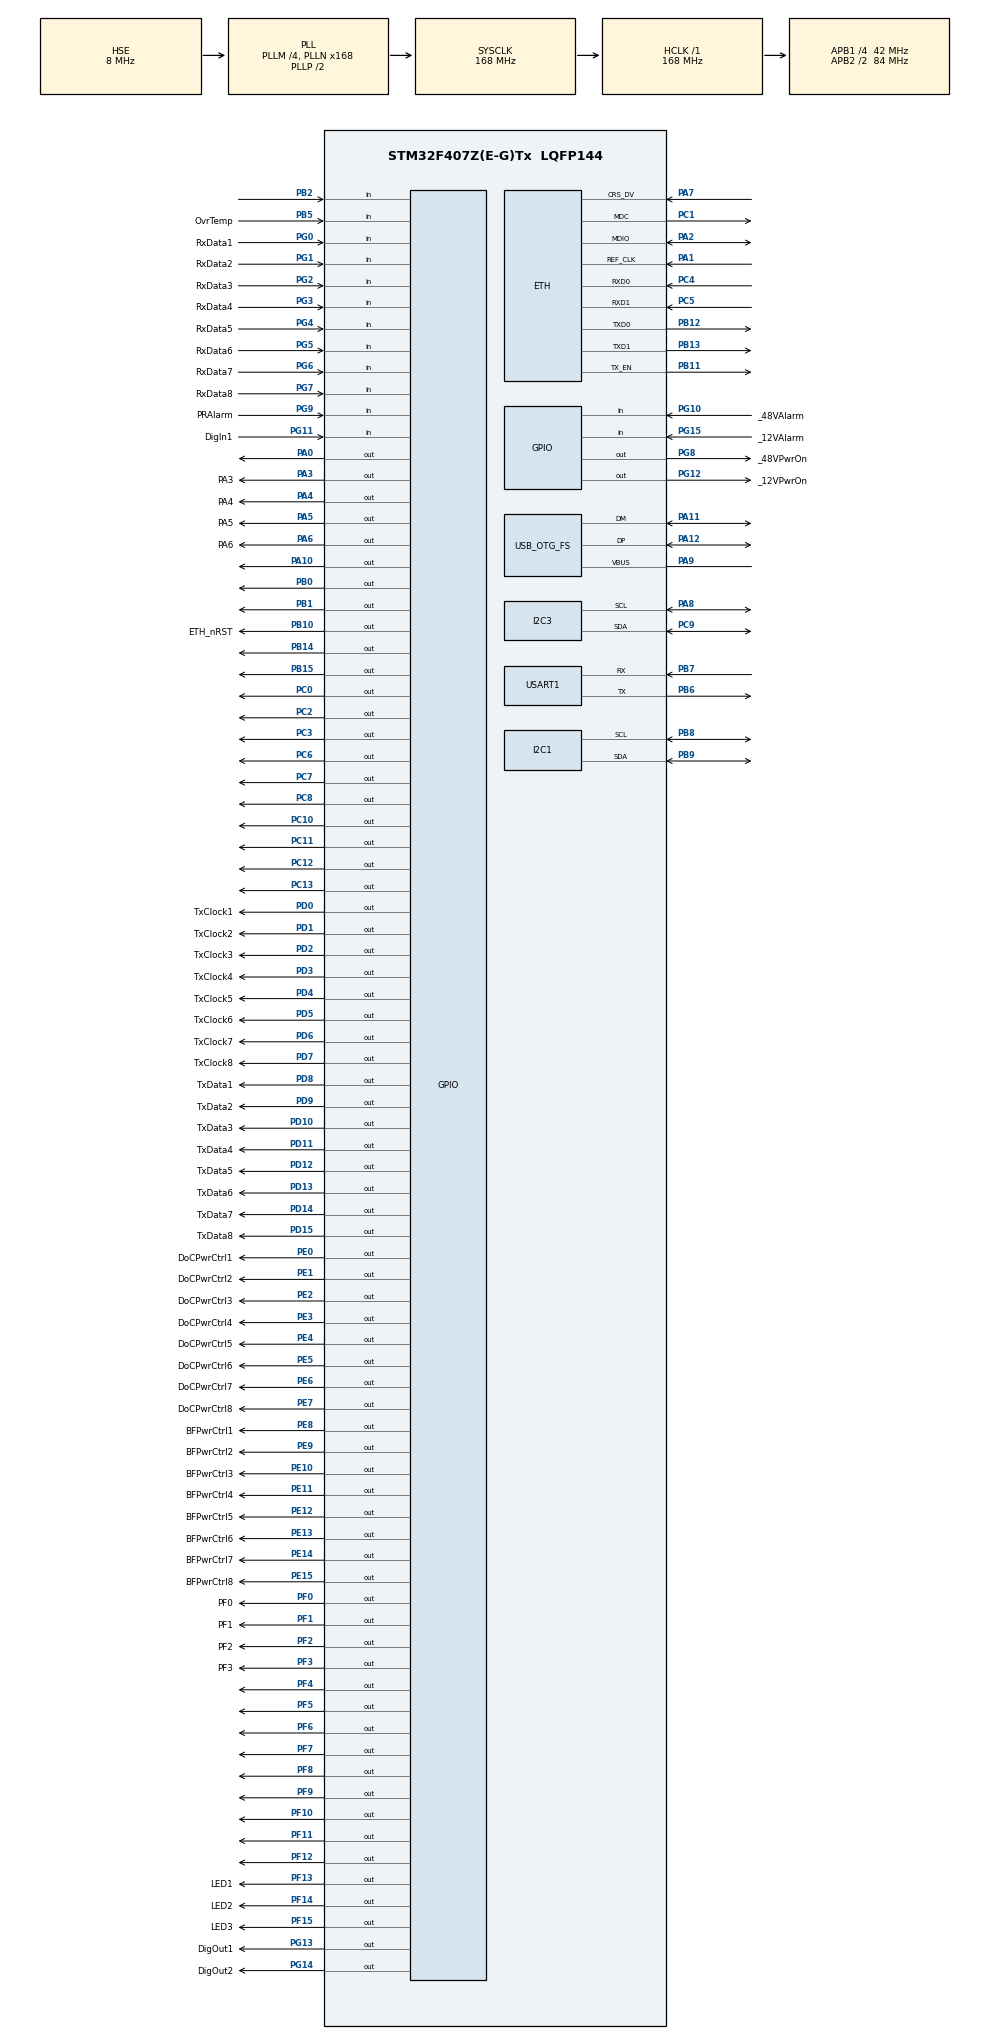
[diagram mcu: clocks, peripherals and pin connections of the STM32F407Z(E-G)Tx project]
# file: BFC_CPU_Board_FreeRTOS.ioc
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ETH.MediaInterface=HAL_ETH_RMII_MODE
ETH.PHY_DUPLEX_STATUS=0x0010
ETH.PHY_ISFR_INT4=0x0010
ETH.PHY_SPEED_STATUS=0x0004
ETH.PHY_SR=0x1F
ETH.RxMode=ETH_RXINTERRUPT_MODE
FREERTOS.Tasks01=defaultTask,24,768,StartDefaultTask,Default,NULL,Dynamic,NULL,NULL;ManageMQTTConn,40,768,StartMQTTConn,Default,NULL,Dynamic,NULL,NULL;PingWatchdog,8,768,StartPingWD,Default,NULL,Dynamic,NULL,NULL;Telemetry,24,768,StartTelemetry,Default,NULL,Dynamic,NULL,NULL
FREERTOS.configCHECK_FOR_STACK_OVERFLOW=2
FREERTOS.configENABLE_FPU=1
FREERTOS.configLIBRARY_LOWEST_INTERRUPT_PRIORITY=14
FREERTOS.configMINIMAL_STACK_SIZE=768
FREERTOS.configTOTAL_HEAP_SIZE=32768
FREERTOS.configUSE_NEWLIB_REENTRANT=1
I2C1.I2C_Mode=I2C_Fast
I2C3.I2C_Mode=I2C_Fast
Mcu.Family=STM32F4
Mcu.Name=STM32F407Z(E-G)Tx
Mcu.Package=LQFP144
NVIC.ETH_IRQn=true\:5\:0\:false\:false\:true\:true\:false\:true\:true
NVIC.I2C1_EV_IRQn=true\:12\:0\:true\:false\:true\:true\:true\:true\:true
NVIC.I2C3_EV_IRQn=true\:13\:0\:true\:false\:true\:true\:true\:true\:true
NVIC.OTG_FS_IRQn=true\:10\:0\:true\:false\:true\:true\:false\:true\:true
NVIC.PriorityGroup=NVIC_PRIORITYGROUP_4
NVIC.TIM2_IRQn=true\:11\:0\:true\:false\:true\:true\:true\:true\:true
NVIC.TIM7_IRQn=true\:14\:0\:true\:false\:true\:false\:false\:true\:true
NVIC.TimeBase=TIM7_IRQn
NVIC.TimeBaseIP=TIM7
NVIC.USART1_IRQn=true\:14\:0\:true\:false\:true\:true\:true\:true\:true
PA0-WKUP.Signal=GPIO_Output
PA1.Mode=RMII
PA1.Signal=ETH_REF_CLK
PA10.Signal=GPIO_Output
PA11.Mode=Device_Only
PA11.Signal=USB_OTG_FS_DM
PA12.Mode=Device_Only
PA12.Signal=USB_OTG_FS_DP
PA13.Mode=JTAG_5_pins
PA13.Signal=SYS_JTMS-SWDIO
PA14.Mode=JTAG_5_pins
PA14.Signal=SYS_JTCK-SWCLK
PA15.Mode=JTAG_5_pins
PA15.Signal=SYS_JTDI
PA2.Mode=RMII
PA2.Signal=ETH_MDIO
PA3.GPIO_Label=PA3
PA3.Signal=GPIO_Output
PA4.GPIO_Label=PA4
PA4.Signal=GPIO_Output
PA5.GPIO_Label=PA5
PA5.Signal=GPIO_Output
PA6.GPIO_Label=PA6
PA6.Signal=GPIO_Output
PA7.Mode=RMII
PA7.Signal=ETH_CRS_DV
PA8.Mode=I2C
PA8.Signal=I2C3_SCL
PA9.Mode=Activate_VBUS
PA9.Signal=USB_OTG_FS_VBUS
PB0.Signal=GPIO_Output
PB1.Signal=GPIO_Output
PB10.GPIO_Label=ETH_nRST
PB10.GPIO_Speed=GPIO_SPEED_FREQ_LOW
PB10.PinState=GPIO_PIN_SET
PB10.Signal=GPIO_Output
PB11.Mode=RMII
PB11.Signal=ETH_TX_EN
PB12.Mode=RMII
PB12.Signal=ETH_TXD0
PB13.Mode=RMII
PB13.Signal=ETH_TXD1
PB14.Signal=GPIO_Output
PB15.Signal=GPIO_Output
PB2.Signal=GPIO_Input
PB3.Mode=JTAG_5_pins
PB3.Signal=SYS_JTDO-SWO
PB4.Mode=JTAG_5_pins
PB4.Signal=SYS_JTRST
PB5.GPIO_Label=OvrTemp
PB5.Signal=GPIO_Input
PB6.Mode=Asynchronous
PB6.Signal=USART1_TX
PB7.Mode=Asynchronous
PB7.Signal=USART1_RX
PB8.Mode=I2C
PB8.Signal=I2C1_SCL
PB9.Mode=I2C
PB9.Signal=I2C1_SDA
PC0.Signal=GPIO_Output
PC1.Mode=RMII
PC1.Signal=ETH_MDC
PC10.Signal=GPIO_Output
PC11.Signal=GPIO_Output
PC12.Signal=GPIO_Output
PC13-ANTI_TAMP.Signal=GPIO_Output
PC14-OSC32_IN.Mode=LSE-External-Oscillator
PC14-OSC32_IN.Signal=RCC_OSC32_IN
PC15-OSC32_OUT.Mode=LSE-External-Oscillator
PC15-OSC32_OUT.Signal=RCC_OSC32_OUT
PC2.Signal=GPIO_Output
PC3.Signal=GPIO_Output
PC4.Mode=RMII
PC4.Signal=ETH_RXD0
PC5.Mode=RMII
PC5.Signal=ETH_RXD1
PC6.Signal=GPIO_Output
PC7.Signal=GPIO_Output
PC8.Signal=GPIO_Output
PC9.Mode=I2C
PC9.Signal=I2C3_SDA
PD0.GPIO_Label=TxClock1
PD0.GPIO_ModeDefaultOutputPP=GPIO_MODE_OUTPUT_PP
PD0.GPIO_Speed=GPIO_SPEED_FREQ_HIGH
PD0.Signal=GPIO_Output
PD1.GPIO_Label=TxClock2
PD1.GPIO_ModeDefaultOutputPP=GPIO_MODE_OUTPUT_PP
PD1.GPIO_Speed=GPIO_SPEED_FREQ_HIGH
PD1.Signal=GPIO_Output
PD10.GPIO_Label=TxData3
PD10.GPIO_ModeDefaultOutputPP=GPIO_MODE_OUTPUT_PP
PD10.GPIO_Speed=GPIO_SPEED_FREQ_HIGH
PD10.Signal=GPIO_Output
PD11.GPIO_Label=TxData4
PD11.GPIO_ModeDefaultOutputPP=GPIO_MODE_OUTPUT_PP
PD11.GPIO_Speed=GPIO_SPEED_FREQ_HIGH
PD11.Signal=GPIO_Output
PD12.GPIO_Label=TxData5
PD12.GPIO_ModeDefaultOutputPP=GPIO_MODE_OUTPUT_PP
PD12.GPIO_Speed=GPIO_SPEED_FREQ_HIGH
PD12.Signal=GPIO_Output
PD13.GPIO_Label=TxData6
PD13.GPIO_ModeDefaultOutputPP=GPIO_MODE_OUTPUT_PP
PD13.GPIO_Speed=GPIO_SPEED_FREQ_HIGH
PD13.Signal=GPIO_Output
PD14.GPIO_Label=TxData7
PD14.GPIO_ModeDefaultOutputPP=GPIO_MODE_OUTPUT_PP
PD14.GPIO_Speed=GPIO_SPEED_FREQ_HIGH
PD14.Signal=GPIO_Output
PD15.GPIO_Label=TxData8
PD15.GPIO_ModeDefaultOutputPP=GPIO_MODE_OUTPUT_PP
PD15.GPIO_Speed=GPIO_SPEED_FREQ_HIGH
PD15.Signal=GPIO_Output
PD2.GPIO_Label=TxClock3
PD2.GPIO_ModeDefaultOutputPP=GPIO_MODE_OUTPUT_PP
PD2.GPIO_Speed=GPIO_SPEED_FREQ_HIGH
PD2.Signal=GPIO_Output
PD3.GPIO_Label=TxClock4
PD3.GPIO_ModeDefaultOutputPP=GPIO_MODE_OUTPUT_PP
PD3.GPIO_Speed=GPIO_SPEED_FREQ_HIGH
PD3.Signal=GPIO_Output
PD4.GPIO_Label=TxClock5
PD4.GPIO_ModeDefaultOutputPP=GPIO_MODE_OUTPUT_PP
PD4.GPIO_Speed=GPIO_SPEED_FREQ_HIGH
PD4.Signal=GPIO_Output
PD5.GPIO_Label=TxClock6
PD5.GPIO_ModeDefaultOutputPP=GPIO_MODE_OUTPUT_PP
PD5.GPIO_Speed=GPIO_SPEED_FREQ_HIGH
PD5.Signal=GPIO_Output
PD6.GPIO_Label=TxClock7
PD6.GPIO_ModeDefaultOutputPP=GPIO_MODE_OUTPUT_PP
PD6.GPIO_Speed=GPIO_SPEED_FREQ_HIGH
PD6.Signal=GPIO_Output
PD7.GPIO_Label=TxClock8
PD7.GPIO_ModeDefaultOutputPP=GPIO_MODE_OUTPUT_PP
PD7.GPIO_Speed=GPIO_SPEED_FREQ_HIGH
PD7.Signal=GPIO_Output
PD8.GPIO_Label=TxData1
PD8.GPIO_ModeDefaultOutputPP=GPIO_MODE_OUTPUT_PP
PD8.GPIO_Speed=GPIO_SPEED_FREQ_HIGH
PD8.Signal=GPIO_Output
PD9.GPIO_Label=TxData2
PD9.GPIO_ModeDefaultOutputPP=GPIO_MODE_OUTPUT_PP
PD9.GPIO_Speed=GPIO_SPEED_FREQ_HIGH
PD9.Signal=GPIO_Output
PE0.GPIO_Label=DoCPwrCtrl1
PE0.Signal=GPIO_Output
PE1.GPIO_Label=DoCPwrCtrl2
PE1.Signal=GPIO_Output
PE10.GPIO_Label=BFPwrCtrl3
PE10.Signal=GPIO_Output
PE11.GPIO_Label=BFPwrCtrl4
PE11.Signal=GPIO_Output
PE12.GPIO_Label=BFPwrCtrl5
PE12.Signal=GPIO_Output
PE13.GPIO_Label=BFPwrCtrl6
PE13.Signal=GPIO_Output
PE14.GPIO_Label=BFPwrCtrl7
PE14.Signal=GPIO_Output
PE15.GPIO_Label=BFPwrCtrl8
PE15.Signal=GPIO_Output
PE2.GPIO_Label=DoCPwrCtrl3
PE2.Signal=GPIO_Output
PE3.GPIO_Label=DoCPwrCtrl4
PE3.Signal=GPIO_Output
PE4.GPIO_Label=DoCPwrCtrl5
PE4.Signal=GPIO_Output
PE5.GPIO_Label=DoCPwrCtrl6
PE5.Signal=GPIO_Output
PE6.GPIO_Label=DoCPwrCtrl7
PE6.Signal=GPIO_Output
PE7.GPIO_Label=DoCPwrCtrl8
PE7.Signal=GPIO_Output
PE8.GPIO_Label=BFPwrCtrl1
PE8.Signal=GPIO_Output
PE9.GPIO_Label=BFPwrCtrl2
PE9.Signal=GPIO_Output
PF0.GPIO_Label=PF0
PF0.Signal=GPIO_Output
PF1.GPIO_Label=PF1
PF1.Signal=GPIO_Output
PF10.Signal=GPIO_Output
PF11.Signal=GPIO_Output
PF12.Signal=GPIO_Output
PF13.GPIO_Label=LED1
PF13.Signal=GPIO_Output
PF14.GPIO_Label=LED2
PF14.Signal=GPIO_Output
PF15.GPIO_Label=LED3
PF15.Signal=GPIO_Output
PF2.GPIO_Label=PF2
PF2.Signal=GPIO_Output
PF3.GPIO_Label=PF3
PF3.Signal=GPIO_Output
PF4.Signal=GPIO_Output
PF5.Signal=GPIO_Output
PF6.Signal=GPIO_Output
PF7.Signal=GPIO_Output
PF8.Signal=GPIO_Output
PF9.Signal=GPIO_Output
PG0.GPIO_Label=RxData1
PG0.Signal=GPIO_Input
PG1.GPIO_Label=RxData2
PG1.Signal=GPIO_Input
PG10.GPIO_Label=_48VAlarm
PG10.Signal=GPIO_Input
PG11.GPIO_Label=DigIn1
PG11.Signal=GPIO_Input
PG12.GPIO_Label=_12VPwrOn
PG12.Signal=GPIO_Output
PG13.GPIO_Label=DigOut1
PG13.Signal=GPIO_Output
PG14.GPIO_Label=DigOut2
PG14.Signal=GPIO_Output
PG15.GPIO_Label=_12VAlarm
PG15.Signal=GPIO_Input
PG2.GPIO_Label=RxData3
PG2.Signal=GPIO_Input
PG3.GPIO_Label=RxData4
PG3.Signal=GPIO_Input
PG4.GPIO_Label=RxData5
PG4.Signal=GPIO_Input
PG5.GPIO_Label=RxData6
PG5.Signal=GPIO_Input
PG6.GPIO_Label=RxData7
PG6.Signal=GPIO_Input
PG7.GPIO_Label=RxData8
PG7.Signal=GPIO_Input
PG8.GPIO_Label=_48VPwrOn
PG8.Signal=GPIO_Output
PG9.GPIO_Label=PRAlarm
PG9.Signal=GPIO_Input
PH0-OSC_IN.Mode=HSE-External-Oscillator
PH0-OSC_IN.Signal=RCC_OSC_IN
PH1-OSC_OUT.Mode=HSE-External-Oscillator
PH1-OSC_OUT.Signal=RCC_OSC_OUT
ProjectManager.HeapSize=0x200
ProjectManager.StackSize=0x400
ProjectManager.TargetToolchain=STM32CubeIDE
RCC.48MHZClocksFreq_Value=48000000
RCC.AHBFreq_Value=168000000
RCC.APB1CLKDivider=RCC_HCLK_DIV4
RCC.APB1Freq_Value=42000000
RCC.APB1TimFreq_Value=84000000
RCC.APB2CLKDivider=RCC_HCLK_DIV2
RCC.APB2Freq_Value=84000000
RCC.APB2TimFreq_Value=168000000
RCC.CortexFreq_Value=168000000
RCC.HCLKFreq_Value=168000000
RCC.HSE_VALUE=8000000
RCC.HSI_VALUE=16000000
RCC.PLLM=4
RCC.PLLN=168
RCC.PLLQ=7
RCC.RCC_RTC_Clock_Source=RCC_RTCCLKSOURCE_LSE
RCC.RCC_RTC_Clock_SourceVirtual=RCC_RTCCLKSOURCE_LSE
RCC.SYSCLKFreq_VALUE=168000000
RCC.SYSCLKSource=RCC_SYSCLKSOURCE_PLLCLK
RCC.VCOOutputFreq_Value=336000000
RTC.Format=RTC_FORMAT_BCD
RTC.Year=22
TIM2.AutoReloadPreload=TIM_AUTORELOAD_PRELOAD_ENABLE
TIM2.CounterMode=TIM_COUNTERMODE_DOWN
TIM2.Period=83999999
TIM6.AutoReloadPreload=TIM_AUTORELOAD_PRELOAD_ENABLE
TIM6.Prescaler=83
USART1.VirtualMode=VM_ASYNC
USB_DEVICE.CLASS_NAME_FS=DFU
USB_DEVICE.VirtualMode-DFU_FS=Dfu
USB_DEVICE.VirtualModeFS=Dfu_FS
USB_OTG_FS.VirtualMode=Device_Only
VP_CRC_VS_CRC.Mode=CRC_Activate
VP_FREERTOS_VS_CMSIS_V2.Mode=CMSIS_V2
VP_RNG_VS_RNG.Mode=RNG_Activate
VP_RTC_VS_RTC_Activate.Mode=RTC_Enabled
VP_RTC_VS_RTC_Calendar.Mode=RTC_Calendar
VP_SYS_VS_tim7.Mode=TIM7
VP_TIM2_VS_ClockSourceINT.Mode=Internal
VP_TIM6_VS_ClockSourceINT.Mode=Enable_Timer
VP_USB_DEVICE_VS_USB_DEVICE_DFU_FS.Mode=DFU_FS
board=custom

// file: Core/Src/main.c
/* USER CODE BEGIN Header */
/**
  ******************************************************************************
  * @file           : main.c
  * @brief          : Main program body
  ******************************************************************************
  * @attention
  *
  * Copyright (c) 2023 STMicroelectronics.
  * All rights reserved.
  *
  * This software is licensed under terms that can be found in the LICENSE file
  * in the root directory of this software component.
  * If no LICENSE file comes with this software, it is provided AS-IS.
  *
  ******************************************************************************
  */
/* USER CODE END Header */
#include "main.h"
#include "cmsis_os.h"
#include "crc.h"
#include "eth.h"
#include "i2c.h"
#include "iwdg.h"
#include "rng.h"
#include "rtc.h"
#include "tim.h"
#include "usart.h"
#include "usb_device.h"
#include "gpio.h"

/* USER CODE BEGIN Includes */
#include "FreeRTOS.h"
#include "cJSON.h"
//#include <stdio.h>
#include "bfc_config.h"
/* USER CODE END Includes */

/* USER CODE BEGIN PV */

//uint8_t ucHeap[ configTOTAL_HEAP_SIZE ] __attribute__ ((section (".ccmram")));

struct bf_struct beamformer[8] __attribute__ ((section (".ccmram")));
struct bfc_struct bfController __attribute__ ((section (".ccmram")));
unsigned long unixTime = 0;
unsigned long nextPointTime = LONG_TIME_AWAY;

/* USER CODE END PV */

void SystemClock_Config(void);
void MX_FREERTOS_Init(void);
/* USER CODE BEGIN PFP */
void intTo6bits(int value, char *buffer);
void intToXbits(int value, char *buffer, int bits);
void gen_bitstring(int xdelays[], int ydelays[], char *outlist);
void send_bitstring_en(uint8_t bfEnable, float *bf_temp, uint8_t *bf_flags);
void sntp_SetSystemTime(uint32_t sec, uint32_t us);
void parsePointing(const uint8_t *data, int len);
void parseBFPower(const uint8_t *data, int len);
void parseDoCPower(const uint8_t *data, int len);
void doBFTest();
void sendBFPointing();

extern void sendPointingResult();
extern void sendLog(const char *logLevel, const char *logMsg);
/* USER CODE END PFP */

/* USER CODE BEGIN 0 */

void ActivateEthPhy(void) // Release LAN8742 reset pin
{
	HAL_GPIO_WritePin(ETH_nRST_GPIO_Port, ETH_nRST_Pin, GPIO_PIN_SET);
}

void DeactivateEthPhy(void) // Hold LAN8742 in reset
{
	HAL_GPIO_WritePin(ETH_nRST_GPIO_Port, ETH_nRST_Pin, GPIO_PIN_RESET);
}

void delay_us(unsigned int us)
{
	__HAL_TIM_SET_COUNTER(&htim6,0);  // set the counter value a 0
	while (__HAL_TIM_GET_COUNTER(&htim6) < us);  // wait for the counter to reach the us input in the parameter
}

#ifdef __GNUC__
#define PUTCHAR_PROTOTYPE int __io_putchar(int ch)
#else
#define PUTCHAR_PROTOTYPE int fputc(int ch, FILE *f)
#endif
PUTCHAR_PROTOTYPE
{
	// Uncomment one line to select where printf() commands send their characters
	// HAL_UART for UART1 pins, or ITM_SendChar for the SWV debugger
	//HAL_UART_Transmit(&huart1, (uint8_t *)&ch, 1, HAL_MAX_DELAY);
	ITM_SendChar(ch);
	return ch;
}

/* USER CODE END 0 */

int main(void)
{

  /* MCU Configuration--------------------------------------------------------*/

  /* Reset of all peripherals, Initializes the Flash interface and the Systick. */
  HAL_Init();

  /* Configure the system clock */
  SystemClock_Config();

  /* Initialize all configured peripherals */
  MX_GPIO_Init();
  MX_I2C1_Init();
  MX_I2C3_Init();
  MX_USART1_UART_Init();
  MX_RTC_Init();
  MX_CRC_Init();
  MX_RNG_Init();
  MX_TIM6_Init();
  MX_TIM2_Init();
  MX_ETH_Init();
  MX_IWDG_Init();
  /* USER CODE BEGIN 2 */
  HAL_TIM_Base_Start(&htim6); // Start the 1 us timer
  HAL_TIM_Base_Start_IT(&htim2); // Start the 1 s overflow unixTime timer, enable interrupt

  ActivateEthPhy();
  GPIOD->BSRR = 0xFFFF0000; // Set Port D all bits/clocks low
  HAL_Delay(200);

  /* USER CODE END 2 */

  /* Init scheduler */
  osKernelInitialize();  /* Call init function for freertos objects (in freertos.c) */
  MX_FREERTOS_Init();

  // Pat the watchdog
  HAL_IWDG_Refresh(&hiwdg);

  /* Start scheduler */
  osKernelStart();

  /* We should never get here as control is now taken by the scheduler */
  /* Infinite loop */
  while (1)
  {

  }
}

void SystemClock_Config(void)
{
  RCC_OscInitTypeDef RCC_OscInitStruct = {0};
  RCC_ClkInitTypeDef RCC_ClkInitStruct = {0};

  /** Configure the main internal regulator output voltage
  */
  __HAL_RCC_PWR_CLK_ENABLE();
  __HAL_PWR_VOLTAGESCALING_CONFIG(PWR_REGULATOR_VOLTAGE_SCALE1);

  /** Initializes the RCC Oscillators according to the specified parameters
  * in the RCC_OscInitTypeDef structure.
  */
  RCC_OscInitStruct.OscillatorType = RCC_OSCILLATORTYPE_LSI | RCC_OSCILLATORTYPE_HSE | RCC_OSCILLATORTYPE_LSE;
  RCC_OscInitStruct.HSEState = RCC_HSE_ON;
  RCC_OscInitStruct.LSEState = RCC_LSE_ON;
  RCC_OscInitStruct.LSIState = RCC_LSI_ON;
  RCC_OscInitStruct.PLL.PLLState = RCC_PLL_ON;
  RCC_OscInitStruct.PLL.PLLSource = RCC_PLLSOURCE_HSE;
  RCC_OscInitStruct.PLL.PLLM = 4;
  RCC_OscInitStruct.PLL.PLLN = 168;
  RCC_OscInitStruct.PLL.PLLP = RCC_PLLP_DIV2;
  RCC_OscInitStruct.PLL.PLLQ = 7;
  if (HAL_RCC_OscConfig(&RCC_OscInitStruct) != HAL_OK)
  {
    Error_Handler();
  }

  /** Initializes the CPU, AHB and APB buses clocks
  */
  RCC_ClkInitStruct.ClockType = RCC_CLOCKTYPE_HCLK|RCC_CLOCKTYPE_SYSCLK
                              |RCC_CLOCKTYPE_PCLK1|RCC_CLOCKTYPE_PCLK2;
  RCC_ClkInitStruct.SYSCLKSource = RCC_SYSCLKSOURCE_PLLCLK;
  RCC_ClkInitStruct.AHBCLKDivider = RCC_SYSCLK_DIV1;
  RCC_ClkInitStruct.APB1CLKDivider = RCC_HCLK_DIV4;
  RCC_ClkInitStruct.APB2CLKDivider = RCC_HCLK_DIV2;

  if (HAL_RCC_ClockConfig(&RCC_ClkInitStruct, FLASH_LATENCY_5) != HAL_OK)
  {
    Error_Handler();
  }
}

/* USER CODE BEGIN 4 */
void gen_bitstring(int xdelays[], int ydelays[], char *outstring)
/* Given two arrays of 16x 16-bit integers representing the X and Y delays, return a string containing 253
 * characters each '1' or '0' representing the bitstream to send to the beamformer.
 */
{
	int i=0, x=0, y=0, chksum=0;
	char buffer[sizeof(int)*8+1] = "";
	char xdelays_b[16*6+1] = "", ydelays_b[16*6+1] = ""; // Packed 16 x 6-bit (96 bits) binary delays as strings
	int chk_words[12];

	strcpy(outstring, "00000000111100000000000000000000"); // Preamble 32 bits
	i = 32; // Start adding bits after preamble at pos 32

	// Convert 16x xdelay integers into 6-bit binary values packed in a 96 bit string
	for (x=0; x<=15; x++) { // For each integer in the xdelays array
		intToXbits(xdelays[x], buffer, 6);
		strcat(xdelays_b, buffer);
	}
	// Convert 16x ydelay integers into 6-bit binary values packed in a 96 bit string
	for (y=0; y<=15; y++) { // For each integer in the ydelays array
		intToXbits(ydelays[y], buffer, 6);
		strcat(ydelays_b, buffer);
	}

	// Extract first 6x 16-bit integers from x delay packed string and add to output
	for (x=0; x<=5; x++) { // For each word in the first group of 6
		for (y=0; y<=16; y++) { // For each bit in the 16-bit word
			if (y != 16) {
				outstring[i] = xdelays_b[x*16+y];
				buffer[y] = xdelays_b[x*16+y];
			}
			else {
				outstring[i] = '1'; // Add 1's for spacing between words on output
			}
			i++;
		}
		buffer[16] = '\0';
		chk_words[x] = (int) strtol(buffer, NULL ,2);
	}
	// Extract the second 6x 16-bit integers from y delay packed string and add to output
	for (x=6; x<=11; x++) { // For each word in the second group of 6
		for (y=0; y<=16; y++) { // For each bit in the 16-bit word
			if (y != 16) {
				outstring[i] = ydelays_b[(x-6)*16+y];
				buffer[y] = ydelays_b[(x-6)*16+y];
			}
			else {
				outstring[i] = '1'; // Add 1's for spacing between words on output
			}
			i++;
		}
		buffer[16] = '\0';
		chk_words[x] = (int) strtol(buffer, NULL ,2);
	}

	// Calculate checksum: the 12x 16-bit packed delay words XORed together
	for (x=0; x<=11; x++) { // For each 16-bit word in the packed bit strings array
		chksum = chksum ^ chk_words[x]; // Bitwise XOR
	}

	// Add 16-bit checksum to output string
	intToXbits(chksum, buffer, 16);
	for (x=0; x<=15; x++) { // For each bit in the checksum buffer
		if(buffer[x] == '0' || buffer[x] == '1') outstring[i] = buffer[x];
		else outstring[i] = '0';
		i++;
	}

	// Add one more 1 for good measure
	outstring[i] = '1';
	i++;

	// Add termination null
	outstring[i] = '\0';

	//printf("Outstring %d bits: %s\n", strlen(outstring), outstring);
}

void intToXbits(int value, char *buffer, int bits) {
/*
 * Converts the least-significant <bits> bits from <value> into a string of
 * '1' and '0' chars in <*buffer> terminated with a \0. Caution: Does no
 * checking of realistic values or if <*buffer> is large enough to hold the result.
 */
	int i = 0;
	for (int mask = 0x01 << (bits - 1); mask > 0; mask >>= 1) {
		buffer[i++] = (value & mask) ? '1':'0';
	}
	buffer[i++] = '\0';
}

void send_bitstring_en(uint8_t bfEnable, float *bf_temp, uint8_t *bf_flags)
/*
 * outstring is a 253 char array of '0' or '1' representing the bitstream to send. This is clocked out of all
 * enabled pins simultaneously followed by 24 more clocks to read back the temperature and flags from the beamformers.
 * Each beamformer has an outstring in its struct to send.
 * Sending to each BF is enabled by setting the corresponding bit in bfEnable.
 */
// bit time 20 us
{
	const int bittime = 20; // us
	const uint32_t clockHigh = bfEnable;
	const uint32_t clockLow = bfEnable << 16;
	int i,j, indata[30], rawtemps[8];
	const uint32_t bitmask[32] = { 0x1, 0x2, 0x4, 0x8, \
							  0x10, 0x20, 0x40, 0x80,\
							  0x100, 0x200, 0x400, 0x800,\
							  0x1000, 0x2000, 0x4000, 0x8000,\
							  0x10000, 0x20000, 0x40000, 0x80000,\
							  0x100000, 0x200000, 0x400000, 0x800000,\
							  0x1000000, 0x2000000, 0x4000000, 0x8000000,\
							  0x10000000, 0x20000000, 0x40000000, 0x80000000};

	taskENTER_CRITICAL(); // Disable interrupts while we send/receive data
	// Clock out 253 bits on all data/clock lines
	for (i=0; i<253; i++) {
		int portD = 0;
		for (j=0; j<=7; j++) { // For each beamformer
			if (beamformer[j].outstring[i] == '1' && (bfEnable && bitmask[j])) {
				portD |= bitmask[j+8];
			}
			else {
				portD |= bitmask[j+24];
			}
		}
		GPIOD->BSRR = portD;
		delay_us(bittime / 4);
		GPIOD->BSRR = clockHigh;
		delay_us(bittime / 2);
		GPIOD->BSRR = clockLow;
		delay_us(bittime / 4);
	}

	// Clock in 24 bits of temperature and flags data
	GPIOD->BSRR = 0xFFFF0000; // Set Port D all bits/clocks low
	for (i=0; i<24; i++) {
		delay_us(bittime / 4);
		GPIOD->BSRR = clockHigh;
		delay_us(bittime / 4);
		indata[i] = GPIOG->IDR & 0xFF; // Read data from input pins
		delay_us(bittime / 4);
		GPIOD->BSRR = clockLow;
		delay_us(bittime / 4);
	}

	GPIOD->BSRR = 0xFFFF0000; // Set Port D all bits/clocks low
	taskEXIT_CRITICAL(); // Enable interrupts again, whole process should take ~5 ms

	osThreadYield();

	// Calculate BF temps
	for (i=0; i<=15; i++) { // First 16 bits are temperature (signed 12-bit value) MSB first
		for (j=0; j<=7; j++) {// Do for all enabled beamformers
			int bit = indata[i] & bitmask[j];
			if (bit) rawtemps[j] |= bitmask[15-i];
			else rawtemps[j] &= ~bitmask[15-i];
		}
	}
	for (i=0; i<=7; i++) {
		if (bfEnable & bitmask[i]) {
			float temp = 0.0625 * (rawtemps[i] & 0xFFF);
			if (rawtemps[i] & 0x1000) temp -= 256.0;
			bf_temp[i] = temp;
			beamformer[i].lastTemp = temp;
		} else {
			bf_temp[i] = -256.0;
		}
	}
	// Next 8 bits are flags (7:4 - checksum ok(128)/bad(224 or 0), 3:0 - invalid, set to 0)
	for (i=16; i<=23; i++) { // Next 8 bits of indata
		for (j=0; j<=7; j++) { // Do for all enabled beamformers
			if (bfEnable & bitmask[j]) {
				int bit = indata[i] & bitmask[j];
				if (bit && i < 20) bf_flags[j] |= bitmask[23-i];
				else bf_flags[j] &= ~bitmask[23-i];
			} else {
				bf_flags[j] = 0;
			}
		}
	}
	for (i=0; i<=7; i++) {
		if (bfEnable & bitmask[i]) beamformer[i].lastFlags = bf_flags[i];
	}
} // send_bitstring_en

void parsePointing(const uint8_t *data, int len) {
	int xdelays[16] = {0}, ydelays[16] = {0};

	if (len > 0) {
		cJSON *command = cJSON_ParseWithLength((const char*) data, len);
		if(command != NULL) {
			cJSON *sendTimeJSON = cJSON_GetObjectItem(command, "time");
			cJSON *bfNumJSON = cJSON_GetObjectItem(command, "bf");
			if (cJSON_IsNumber(bfNumJSON) && cJSON_IsNumber(sendTimeJSON)) {
				if (bfNumJSON->valueint >= 1 && bfNumJSON->valueint <= 8 && sendTimeJSON->valuedouble > unixTime + 2) {
					beamformer[bfNumJSON->valueint - 1].nextPointTime = sendTimeJSON->valueint;
					if (sendTimeJSON->valuedouble < nextPointTime) nextPointTime = sendTimeJSON->valuedouble;
					cJSON *xdelayArray = cJSON_GetObjectItem(command, "xdelays");
					if(cJSON_IsArray(xdelayArray)) {
						cJSON *delayValue = NULL;
						int i = 0;
						cJSON_ArrayForEach(delayValue, xdelayArray) {
							xdelays[i] = delayValue->valueint;
							beamformer[bfNumJSON->valueint - 1].nextXDelays[i] = delayValue->valueint;
							i++;
						}
					}
					cJSON *ydelayArray = cJSON_GetObjectItem(command, "ydelays");
					if(cJSON_IsArray(ydelayArray)) {
						cJSON *delayValue = NULL;
						int i = 0;
						cJSON_ArrayForEach(delayValue, ydelayArray) {
							ydelays[i] = delayValue->valueint;
							beamformer[bfNumJSON->valueint - 1].nextYDelays[i] = delayValue->valueint;
							i++;
						}
					}
					gen_bitstring(xdelays, ydelays, beamformer[bfNumJSON->valueint - 1].outstring);
					char message[50];
					snprintf(message, 50, "BF: %d point scheduled %.f", bfNumJSON->valueint, sendTimeJSON->valuedouble);
					sendLog("info",message);
				} else {
					sendLog("error", "MQTT Pointing Command Error: \'bf\' and/or \'time\' not valid");
					//printf("MQTT Pointing Command Error: \'bf\' and/or \'time\' not valid");
				}
			}
		} else {
			const char *error_ptr = cJSON_GetErrorPtr();
			if (error_ptr != NULL) {
				//printf("JSON Parse error before: %s\n", error_ptr);
				sendLog("error", "point JSON parse error");
			}
		}
		cJSON_Delete(command);
	}
}

void parseBFPower(const uint8_t *data, int len){

	if (len > 0) {
		cJSON *command = cJSON_ParseWithLength((const char*) data, len);
		if(command != NULL) {
			cJSON *bf_power_array = cJSON_GetObjectItem(command, "bf_power");
			if(cJSON_IsArray(bf_power_array) && cJSON_GetArraySize(bf_power_array) == 8) {
				cJSON *bf_pwr = NULL;
				int i = 0x0100, j = 0;
				int portE = 0;
				cJSON_ArrayForEach(bf_pwr, bf_power_array) {
					if(cJSON_IsTrue(bf_pwr) && beamformer[j].doc_pwr) {
						portE |= i;
						beamformer[j].bf_pwr = 1;
					} else {
						portE |= i << 16;
						beamformer[j].bf_pwr = 0;
					}
					i <<= 1;
					j++;
				}
				GPIOE->BSRR = portE; // Set bit in lowest 16 bits to set pin, set in highest 16 bits to clear pin
				sendLog("info", "bf_power set OK");
			} else {
				sendLog("error","bf_power JSON array error");
			}
		} else {
			const char *error_ptr = cJSON_GetErrorPtr();
			if (error_ptr != NULL) {
				//printf("bf_power JSON Parse error before: %s\n", error_ptr);
				sendLog("error", "bf_power JSON parse error");
			}
		}
		cJSON_Delete(command);
	}
}

void parseDoCPower(const uint8_t *data, int len){

	if (len > 0) {
		cJSON *command = cJSON_ParseWithLength((const char*) data, len);
		if(command != NULL) {
			cJSON *doc_power_array = cJSON_GetObjectItem(command, "doc_power");
			if(cJSON_IsArray(doc_power_array) && cJSON_GetArraySize(doc_power_array) == 8) {
				cJSON *doc_pwr = NULL;
				int i = 0x01, j = 0;
				int portE = 0;
				cJSON_ArrayForEach(doc_pwr, doc_power_array) {
					if(cJSON_IsTrue(doc_pwr)) {
						portE |= i;
						beamformer[j].doc_pwr = 1;
					} else {
						portE |= i << 16;
						beamformer[j].doc_pwr = 0;
						if(beamformer[j].bf_pwr) {
							beamformer[j].bf_pwr = 0;
							portE |= i << 24;
						}
					}
					i <<= 1;
					j++;
				}
				GPIOE->BSRR = portE; // Set bit in lowest 16 bits to set pin, set in highest 16 bits to clear pin
				sendLog("info", "doc_power set OK");
			} else {
				sendLog("error","doc_power JSON array error");
			}
		} else {
			const char *error_ptr = cJSON_GetErrorPtr();
			if (error_ptr != NULL) {
				//printf("DoCPower JSON Parse error before: %s\n", error_ptr);
				sendLog("error", "doc_power JSON parse error");
			}
		}
		cJSON_Delete(command);
	}
}

void doBFTest() {
	int testxdelays[16] = {0,0,0,0,0,0,0,0,0,0,0,0,0,0,0,0};
	int testydelays[16] = {0,0,0,0,0,0,0,0,0,0,0,0,0,0,0,0};
	char output[255];
	char saved_bitstrings[8][255];
	int i, j = 0;

	gen_bitstring(testxdelays, testydelays, output);
	// Save the current beamformer outstrings and set them to 0 delays
	for (i=0; i<=7; i++) { // For each beamformer
		for (j=0; j<255; j++) { // For each bit in the outstrings
			saved_bitstrings[i][j] = beamformer[i].outstring[j];
			beamformer[i].outstring[j] = output[j];
		}
	}
	send_bitstring_en(0xFF, bfController.lastBFTemps, bfController.lastBFFlags);
	bfController.lastPointTime = unixTime;
	bfController.lastBFEnable = 0xFF;
	// Restore the previous beamformer outstrings
	for (i=0; i<=7; i++) { // For each beamformer
		for (j=0; j<255; j++) { // For each bit in the outstrings
			beamformer[i].outstring[j] = saved_bitstrings[i][j];
		}
	}
	for (i=0; i<=7; i++) { // For each beamformer
		for (j=0; j<=15; j++) { // For each delay value
			beamformer[i].lastXDelays[j] = 0;
			beamformer[i].lastYDelays[j] = 0;
		}
		beamformer[i].lastPointTime = unixTime;
	}
	sendPointingResult();
}

void sendBFPointing() {

	uint8_t bfEnable = 0;
	for (int i = 0; i <= 7; i++) { // For each beamformer
		if (beamformer[i].nextPointTime <= unixTime) {
			bfEnable |= (0x01 << i);
			beamformer[i].lastPointTime = unixTime;
			for (int j = 0; j <= 15; j++) { // For each delay value
				beamformer[i].lastXDelays[j] = beamformer[i].nextXDelays[j];
				beamformer[i].lastYDelays[j] = beamformer[i].nextYDelays[j];
				beamformer[i].nextXDelays[j] = 0;
				beamformer[i].nextYDelays[j] = 0;
				beamformer[i].nextPointTime = LONG_TIME_AWAY;
			}
		}
	}
	send_bitstring_en(bfEnable, bfController.lastBFTemps, bfController.lastBFFlags);
	bfController.lastPointTime = unixTime;
	bfController.lastBFEnable = bfEnable;
	sendPointingResult();
}

/* USER CODE END 4 */

void HAL_TIM_PeriodElapsedCallback(TIM_HandleTypeDef *htim)
{
  if (htim->Instance == TIM7) {
    HAL_IncTick();
  }
  /* USER CODE BEGIN Callback 1 */
  if (htim->Instance == TIM2) {
	  unixTime++;
  }
  /* USER CODE END Callback 1 */
}

void Error_Handler(void)
{
  __disable_irq();
  while (1)
  {
  }
}

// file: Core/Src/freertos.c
/* USER CODE BEGIN Header */
/**
  ******************************************************************************
  * File Name          : freertos.c
  * Description        : Code for freertos applications
  ******************************************************************************
  * @attention
  *
  * Copyright (c) 2023 STMicroelectronics.
  * All rights reserved.
  *
  * This software is licensed under terms that can be found in the LICENSE file
  * in the root directory of this software component.
  * If no LICENSE file comes with this software, it is provided AS-IS.
  *
  ******************************************************************************
  */
/* USER CODE END Header */

#include "FreeRTOS.h"
#include "task.h"
#include "main.h"
#include "cmsis_os.h"

/* USER CODE BEGIN Includes */
#include "rng.h"
#include <string.h>
#include "queue.h"
#include "crc.h"

/* FreeRTOS+TCP includes. */
#include "FreeRTOS_IP.h"
#include "FreeRTOS_UDP_IP.h"
#include "FreeRTOS_Sockets.h"

/* MQTT library includes. */
#include "core_mqtt.h"

/* MQTT agent include. */
#include "core_mqtt_agent.h"
#include "core_mqtt_agent_command_functions.h"

#include "cJSON.h"
#include "i2c.h"
#include "bfc_config.h"
#include "rtc.h"
#include <stdio.h>
#include <time.h>
#include "iwdg.h"
#include "core_sntp_client.h"
#include "tim.h"

/*********************** coreMQTT Agent Configurations **********************/
/**
 * @brief The maximum number of pending acknowledgments to track for a single
 * connection.
 *
 * @note The MQTT agent tracks MQTT commands (such as PUBLISH and SUBSCRIBE) th
 * at are still waiting to be acknowledged.  MQTT_AGENT_MAX_OUTSTANDING_ACKS set
 * the maximum number of acknowledgments that can be outstanding at any one time.
 * The higher this number is the greater the agent's RAM consumption will be.
 */
//#define MQTT_AGENT_MAX_OUTSTANDING_ACKS         ( 10U )

/**
 * @brief Time in MS that the MQTT agent task will wait in the Blocked state (so
 * not using any CPU time) for a command to arrive in its command queue before
 * exiting the blocked state so it can call MQTT_ProcessLoop().
 *
 * @note It is important MQTT_ProcessLoop() is called often if there is known
 * MQTT traffic, but calling it too often can take processing time away from
 * lower priority tasks and waste CPU time and power.
 */
//#define MQTT_AGENT_MAX_EVENT_QUEUE_WAIT_TIME    ( 1000 )

/* MQTT Agent ports. */
#include "freertos_agent_message.h"
#include "freertos_command_pool.h"

/* Exponential backoff retry include. */
#include "backoff_algorithm.h"

/* Transport interface implementation include header for plaintext connection. */
#include "transport_plaintext.h"

/* Subscription manager header include. */
//#include "subscription_manager.h"

/* USER CODE END Includes */

/* USER CODE BEGIN PTD */
/**
 * @brief Defines the structure to use as the command callback context
 */
struct MQTTAgentCommandContext
{
    MQTTStatus_t xReturnStatus;
    TaskHandle_t xTaskToNotify;
    uint32_t ulCmdCounter;
    void * pArgs;
};

/**
 * @brief Each compilation unit that consumes the NetworkContext must define it.
 * It should contain a single pointer to the type of your desired transport.
 * When using multiple transports in the same compilation unit, define this pointer as void *.
 *
 * @note Transport stacks are defined in FreeRTOS-Plus/Source/Application-Protocols/network_transport.
 */
struct NetworkContext
{
        PlaintextTransportParams_t * pParams;
};

/* USER CODE END PTD */

/* USER CODE BEGIN PD */

#define MQTT_BROKER_ENDPOINT "10.128.0.1"
#define MQTT_BROKER_PORT 1883

#define SNTP_SERVER "10.128.0.1"
#define SNTP_RESPONSE_TIMEOUT_MS 5000
#define SNTP_BUFFER_SIZE 400
#define SNTP_POLL_INTERVAL 300000 //ms (5 min)

/**
 * @brief This app uses task notifications to signal tasks from MQTT callback
 * functions.  mqttexampleMS_TO_WAIT_FOR_NOTIFICATION defines the time, in ticks,
 * to wait for such a callback.
 */
#define MS_TO_WAIT_FOR_NOTIFICATION            ( 10000 )

/**
 * @brief Size of statically allocated buffers for holding topic names and
 * payloads.
 */
#define STRING_BUFFER_LENGTH                   ( 1200 )

/**
 * @brief Delay for each task between publishes.
 */
//#define DELAY_BETWEEN_PUBLISH_OPERATIONS_MS    ( 1000U )

/**
 * @brief The maximum amount of time in milliseconds to wait for the commands
 * to be posted to the MQTT agent should the MQTT agent's command queue be full.
 * Tasks wait in the Blocked state, so don't use any CPU time.
 */
#define MAX_COMMAND_SEND_BLOCK_TIME_MS         ( 500 )

/**
 * @brief Dimensions the buffer used to serialize and deserialize MQTT packets.
 * @note Specified in bytes.  Must be large enough to hold the maximum
 * anticipated MQTT payload.
 */
#define MQTT_AGENT_NETWORK_BUFFER_SIZE    ( 2000U )

/**
 * @brief The length of the queue used to hold commands for the agent.
 */
#define MQTT_AGENT_COMMAND_QUEUE_LENGTH    ( 5U )

/**
 * @brief Timeout for receiving CONNACK after sending an MQTT CONNECT packet.
 * Defined in milliseconds.
 */
#define CONNACK_RECV_TIMEOUT_MS           ( 1000U )

/**
 * @brief The maximum number of retries for network operation with server.
 */
#define RETRY_MAX_ATTEMPTS                ( 5U )

/**
 * @brief The maximum back-off delay (in milliseconds) for retrying failed operation
 *  with server.
 */
#define RETRY_MAX_BACKOFF_DELAY_MS        ( 5000U )

/**
 * @brief The base back-off delay (in milliseconds) to use for network operation retry
 * attempts.
 */
#define RETRY_BACKOFF_BASE_MS             ( 500U )

/**
 * @brief The maximum time interval in seconds which is allowed to elapse
 *  between two Control Packets.
 *
 *  It is the responsibility of the Client to ensure that the interval between
 *  Control Packets being sent does not exceed the this Keep Alive value. In the
 *  absence of sending any other Control Packets, the Client MUST send a
 *  PINGREQ Packet.
 *//*_RB_ Move to be the responsibility of the agent. */
#define KEEP_ALIVE_INTERVAL_SECONDS       ( 60U )

/**
 * @brief Socket send and receive timeouts to use.  Specified in milliseconds.
 */
#define TRANSPORT_SEND_RECV_TIMEOUT_MS    ( 750 )

/**
 * @brief Used to convert times to/from ticks and milliseconds.
 */
#define MILLISECONDS_PER_SECOND           ( 1000U )
#define MILLISECONDS_PER_TICK             ( MILLISECONDS_PER_SECOND / configTICK_RATE_HZ )

/**
 * @brief The number of command structures to allocate in the pool
 * for the agent.
 */
#define MQTT_COMMAND_CONTEXTS_POOL_SIZE         5

/* USER CODE END PD */

/* USER CODE BEGIN Variables */

/* Application defined structure that will get typedef'ed to CommandContext_t. */
struct CommandContext
{
    TaskHandle_t xTaskToNotify;
    MQTTStatus_t xReturnStatus;
};

extern struct bf_struct beamformer[8];
extern struct bfc_struct bfController;
extern unsigned long unixTime;
extern unsigned long nextPointTime;

unsigned long *uid = (unsigned long *) 0x1FFF7A10; // Memory address of unique identifier, 3x 32-bit values
unsigned long bfc_uid = 0;
char bfc_name[10] = "bfc";
// Command topic (needs to be static while subscription is active (always))
static char cmdTopic[25] = "command/";

unsigned long cmdCounter = 0; // Counter increments every time a message is published by the BFC

// Task monitoring - the default task will check that other tasks are running, which they indicate
// by setting their flag in taskMonitor. If they don't set it, the watchdog won't get pats.
uint8_t taskMonitor = 0; // Flags set by each task to indicate they are running
#define mask_TaskFlags 0x07 // Mask that matches all flags being set
#define taskflag_MQTT 0x01
#define taskflag_Telemetry 0x02
#define taskflag_Logging 0x04

/* The MAC address array is initialised to silly values which get over-written during startup
 * when the UID of the chip is read.*/
static uint8_t ucMACAddress[ 6 ] = { 0x00, 0x11, 0x22, 0x33, 0x44, 0x55 };

/* Define the default network addressing.  Since DHCP isn't used, the BFC will use its UID to
 * compute a psueod-random 4th byte and hope for no clashes.*/
static uint8_t ucIPAddress[ 4 ] = { 10, 128, 60, 1 };
static const uint8_t ucNetMask[ 4 ] = { 255, 255, 0, 0 };
static const uint8_t ucGatewayAddress[ 4 ] = { 10, 128, 0, 1 };
static const uint8_t ucDNSServerAddress[ 4 ] = { 10, 128, 0, 1 };

// From mqtt-agent-task.c
static uint32_t ulGlobalEntryTimeMs;
MQTTAgentContext_t xGlobalMqttAgentContext;
static uint8_t xNetworkBuffer[ MQTT_AGENT_NETWORK_BUFFER_SIZE ];
static MQTTAgentMessageContext_t xCommandQueue;
static PlaintextTransportParams_t xPlaintextTransportParams;
static NetworkContext_t xNetworkContext;
//SubscriptionElement_t xGlobalSubscriptionList[ SUBSCRIPTION_MANAGER_MAX_SUBSCRIPTIONS ];

// Logging message ring buffer, for thread-safe sending of log messages
#define LOGBUFFSIZE 4 // Zero-referenced
struct logMessageStruct {
	char logLevel[6];
	char logMessage[100];
};
struct logMessageStruct logBuffer[LOGBUFFSIZE+2];
uint8_t logHead, logTail = 0;

/* USER CODE END Variables */
/* Definitions for defaultTask */
osThreadId_t defaultTaskHandle;
const osThreadAttr_t defaultTask_attributes = {
  .name = "defaultTask",
  .stack_size = 1024 * 4,
  .priority = (osPriority_t) osPriorityNormal,
};
/* Definitions for ManageMQTTConn */
osThreadId_t ManageMQTTConnHandle;
const osThreadAttr_t ManageMQTTConn_attributes = {
  .name = "ManageMQTTConn",
  .stack_size = 1024 * 4,
  .priority = (osPriority_t) osPriorityAboveNormal,
};
/* Definitions for PingWatchdog */
osThreadId_t PingWatchdogHandle;
const osThreadAttr_t PingWatchdog_attributes = {
  .name = "PingWatchdog",
  .stack_size = 256 * 4,
  .priority = (osPriority_t) osPriorityLow,
};
/* Definitions for Telemetry */
osThreadId_t TelemetryHandle;
const osThreadAttr_t Telemetry_attributes = {
  .name = "Telemetry",
  .stack_size = 768 * 4,
  .priority = (osPriority_t) osPriorityNormal,
};
/* Definitions for Logging */
osThreadId_t LoggingHandle;
const osThreadAttr_t Logging_attributes = {
  .name = "Logging",
  .stack_size = 768 * 4,
  .priority = (osPriority_t) osPriorityNormal,
};

/* Definitions for I2CSendComplete */
osEventFlagsId_t I2CSendCompleteHandle;
const osEventFlagsAttr_t I2CSendComplete_attributes = {
  .name = "I2CSendComplete"
};
/* Definitions for I2CReceiveComplete */
osEventFlagsId_t I2CReceiveCompleteHandle;
const osEventFlagsAttr_t I2CReceiveComplete_attributes = {
  .name = "I2CReceiveComplete"
};
/* Definitions for SendTelemetry */
//osEventFlagsId_t SendTelemetryHandle;
//const osEventFlagsAttr_t SendTelemetry_attributes = {
//  .name = "SendTelemetry"
//};

/* USER CODE BEGIN FunctionPrototypes */

void I2C_Reset(I2C_HandleTypeDef *hi2c);
void readI2Csensor(int sensorNum, float *bf_volts, int *bf_amps, int *bf_fault);
int checkPowerAlarm();
float readTempSensor();
void sendPointingResult();
void sendLog(const char *logLevel, const char *logMsg);
void parseBFTest();
uint32_t uxRand();

/*-----------------------------------------------------------*/

/**
 * @brief Initializes an MQTT context, including transport interface and
 * network buffer.
 *
 * @return `MQTTSuccess` if the initialization succeeds, else `MQTTBadParameter`.
 */
static MQTTStatus_t prvMQTTInit( void );

/**
 * @brief Sends an MQTT Connect packet over the already connected TCP socket.
 *
 * @param[in] pxMQTTContext MQTT context pointer.
 * @param[in] xCleanSession If a clean session should be established.
 *
 * @return `MQTTSuccess` if connection succeeds, else appropriate error code
 * from MQTT_Connect.
 */
static MQTTStatus_t prvMQTTConnect( bool xCleanSession );

/**
 * @brief Connect a TCP socket to the MQTT broker.
 *
 * @param[in] pxNetworkContext Network context.
 *
 * @return `pdPASS` if connection succeeds, else `pdFAIL`.
 */
static BaseType_t prvSocketConnect( NetworkContext_t * pxNetworkContext );

/**
 * @brief Disconnect a TCP connection.
 *
 * @param[in] pxNetworkContext Network context.
 *
 * @return `pdPASS` if disconnect succeeds, else `pdFAIL`.
 */
static BaseType_t prvSocketDisconnect( NetworkContext_t * pxNetworkContext );

/**
 * @brief Callback executed when there is activity on the TCP socket that is
 * connected to the MQTT broker.  If there are no messages in the MQTT agent's
 * command queue then the callback send a message to ensure the MQTT agent
 * task unblocks and can therefore process whatever is necessary on the socket
 * (if anything) as quickly as possible.
 *
 * @param[in] pxSocket Socket with data, unused.
 */
static void prvMQTTClientSocketWakeupCallback( Socket_t pxSocket );

/**
 * @brief Fan out the incoming publishes to the callbacks registered by different
 * tasks. If there are no callbacks registered for the incoming publish, it will be
 * passed to the unsolicited publish handler.
 *
 * @param[in] pMqttAgentContext Agent context.
 * @param[in] packetId Packet ID of publish.
 * @param[in] pxPublishInfo Info of incoming publish.
 */
static void prvIncomingPublishCallback( MQTTAgentContext_t * pMqttAgentContext,
                                        uint16_t packetId,
                                        MQTTPublishInfo_t * pxPublishInfo );

/**
 * @brief Function to attempt to resubscribe to the topics already present in the
 * subscription list.
 *
 * This function will be invoked when this demo requests the broker to
 * reestablish the session and the broker cannot do so. This function will
 * enqueue commands to the MQTT Agent queue and will be processed once the
 * command loop starts.
 *
 * @return `MQTTSuccess` if adding subscribes to the command queue succeeds, else
 * appropriate error code from MQTTAgent_Subscribe.
 * */
static MQTTStatus_t prvHandleResubscribe( void );

/**
 * @brief Passed into MQTTAgent_Subscribe() as the callback to execute when the
 * broker ACKs the SUBSCRIBE message. This callback implementation is used for
 * handling the completion of resubscribes. Any topic filter failed to resubscribe
 * will be removed from the subscription list.
 *
 * See https://freertos.org/mqtt/mqtt-agent-demo.html#example_mqtt_api_call
 *
 * @param[in] pxCommandContext Context of the initial command.
 * @param[in] pxReturnInfo The result of the command.
 */
//static void prvSubscriptionCommandCallback( void * pxCommandContext, MQTTAgentReturnInfo_t * pxReturnInfo );
/**
 * @brief Passed into MQTTAgent_Publish() as the callback to execute when the
 * broker ACKs the PUBLISH message.  Its implementation sends a notification
 * to the task that called MQTTAgent_Publish() to let the task know the
 * PUBLISH operation completed.  It also sets the xReturnStatus of the
 * structure passed in as the command's context to the value of the
 * xReturnStatus parameter - which enables the task to check the status of the
 * operation.
 *
 * See https://freertos.org/mqtt/mqtt-agent-demo.html#example_mqtt_api_call
 *
 * @param[in] pxCommandContext Context of the initial command.
 * @param[in].xReturnStatus The result of the command.
 */
static void prvPublishCommandCallback( MQTTAgentCommandContext_t * pxCommandContext,
                                       MQTTAgentReturnInfo_t * pxReturnInfo );

/**
 * @brief The timer query function provided to the MQTT context.
 *
 * @return Time in milliseconds.
 */
static uint32_t prvGetTimeMs( void );

/**
 * @brief The demo implementation of the @ref SntpResolveDns_t interface to
 * allow the coreSNTP library to resolve DNS name of a time server being
 * used for requesting time from.
 *
 * @param[in] pTimeServer The time-server whose IPv4 address is to be resolved.
 * @param[out] pIpV4Addr This is filled with the resolved IPv4 address of
 * @p pTimeServer.
 */
static BaseType_t resolveDns( const SntpServerInfo_t * pServerAddr,
                        uint32_t * pIpV4Addr );

/**
 * @brief The demo implementation of the @ref SntpGetTime_t interface
 * for obtaining system clock time for the coreSNTP library.
 *
 * @param[out] pTime This will be populated with the current time from
 * the system.
 */
static void sntpClient_GetTime( SntpTimestamp_t * pCurrentTime );

/**
 *
 * @param[in] pTimeServer The time server from whom the time has been received.
 * @param[in] pServerTime The most recent time of the server, @p pTimeServer, sent in its
 * time response.
 * @param[in] clockOffsetMs The value, in milliseconds, of system clock offset relative
 * to the server time calculated by the coreSNTP library. If the value is positive, then
 * the system is BEHIND the server time, and a "slew" clock correction approach is used in
 * this demo. If the value is negative, then the system time is AHEAD of the server time,
 * and a "step" clock correction approach is used in this demo.
 * @param[in] leapSecondInfo This indicates whether there is an upcoming leap second insertion
 * or deletion (according to astronomical time) the last minute of the end of the month that the
 * system time needs to adjust for. Leap second adjustment is valuable for applications that
 * require non-abrupt increment of time for use cases like logging. This demo DOES NOT showcase
 * leap second adjustment in system clock.
 */
static void sntpClient_SetTime( const SntpServerInfo_t * pTimeServer,
                                const SntpTimestamp_t * pServerTime,
                                int64_t clockOffsetMs,
                                SntpLeapSecondInfo_t leapSecondInfo );

/**
 * @brief An implementation of the @ref UdpTransportSendTo_t function
 * of the UDP transport interface to allow the coreSNTP library to perform
 * network operation of sending time request over UDP to the provided time server.
 *
 * @param[in] pNetworkContext This will be the NetworkContext_t context object
 * representing the FreeRTOS UDP socket to use for network send operation.
 * @param[in] serverAddr The IPv4 address of the time server.
 * @param[in] serverPort The port of the server to send data to.
 * @param[in] pBuffer The demo-supplied network buffer of size, SNTP_CONTEXT_NETWORK_BUFFER_SIZE,
 * containing the data to send over the network.
 * @param[in] bytesToSend The size of data in @p pBuffer to send.
 *
 * @return Returns the return code of FreeRTOS UDP send API, FreeRTOS_sendto, which returns
 * 0 for error or timeout OR the number of bytes sent over the network.
 */
static int32_t UdpTransport_Send( sntpNetworkContext_t * pNetworkContext,
                                  uint32_t serverAddr,
                                  uint16_t serverPort,
                                  const void * pBuffer,
                                  uint16_t bytesToSend );

/**
 * @brief An implementation of the @ref UdpTransportRecvFrom_t function
 * of the UDP transport interface to allow the coreSNTP library to perform
 * network operation of reading expected time response over UDP from
 * provided time server.
 *
 * @param[in] pNetworkContext This will be the NetworkContext_t context object
 * representing the FreeRTOS UDP socket to use for network read operation.
 * @param[in] pTimeServer The IPv4 address of the time server to receive data from.
 * @param[in] serverPort The port of the server to receive data from.
 * @param[out] pBuffer The demo-supplied network buffer of size, SNTP_CONTEXT_NETWORK_BUFFER_SIZE,
 * that will be filled with data received from the network.
 * @param[in] bytesToRecv The expected number of bytes to receive from the network
 * for the server response server.
 *
 * @return Returns one of the following:
 * - 0 for timeout in receiving any data from the network (by translating the
 * -pdFREERTOS_ERRNO_EWOULDBLOCK return code from FreeRTOS_recvfrom API )
 *                         OR
 * - The number of bytes read from the network.
 */
static int32_t UdpTransport_Recv( sntpNetworkContext_t * pNetworkContext,
                                  uint32_t serverAddr,
                                  uint16_t serverPort,
                                  void * pBuffer,
                                  uint16_t bytesToRecv );

/* USER CODE END FunctionPrototypes */

void StartDefaultTask(void *argument);
void StartMQTTConn(void *argument);
void StartPingWD(void *argument);
void StartTelemetry(void *argument);
void StartLogging(void *argument);

extern void MX_USB_DEVICE_Init(void);
void MX_FREERTOS_Init(void); /* (MISRA C 2004 rule 8.1) */

void parseTime(const uint8_t *data, int len);

/* Hook prototypes */
void vApplicationStackOverflowHook(xTaskHandle xTask, signed char *pcTaskName);

/* USER CODE BEGIN 4 */
void vApplicationStackOverflowHook(xTaskHandle xTask, signed char *pcTaskName)
{
   /* Run time stack overflow checking is performed if
   configCHECK_FOR_STACK_OVERFLOW is defined to 1 or 2. This hook function is
   called if a stack overflow is detected. */
	printf("Stack Overflow: %s\n", pcTaskName);
}
/* USER CODE END 4 */

void MX_FREERTOS_Init(void) {

  /* Create the thread(s) */
  /* creation of defaultTask */
  defaultTaskHandle = osThreadNew(StartDefaultTask, NULL, &defaultTask_attributes);

  /* creation of ManageMQTTConn */
  //ManageMQTTConnHandle = osThreadNew(StartMQTTConn, NULL, &ManageMQTTConn_attributes);

  /* creation of Telemetry */
  TelemetryHandle = osThreadNew(StartTelemetry, NULL, &Telemetry_attributes);

  // Most tasks are started in the network status callback when the network is up.

  /* USER CODE BEGIN RTOS_EVENTS */

  /* creation of I2CSendComplete */
  I2CSendCompleteHandle = osEventFlagsNew(&I2CSendComplete_attributes);

  /* creation of I2CReceiveComplete */
  I2CReceiveCompleteHandle = osEventFlagsNew(&I2CReceiveComplete_attributes);

  /* creation of SendTelemetry */
  //SendTelemetryHandle = osEventFlagsNew(&SendTelemetry_attributes);

  /* USER CODE END RTOS_EVENTS */

}

void StartDefaultTask(void *argument) {
BaseType_t xReturn;

  /* init code for USB_DEVICE */
  MX_USB_DEVICE_Init();
  /* USER CODE BEGIN StartDefaultTask */

  HAL_IWDG_Refresh(&hiwdg); // Pat the watchdog

  // Calculate a quasi-unique 32-bit value to use as MAC and create BFC name
  bfc_uid = HAL_CRC_Calculate(&hcrc, uid, 3);
  uint8_t idByte1 = (bfc_uid >> 16) & 0xFF;
  uint8_t idByte2 = (bfc_uid >> 8) & 0xFF;
  uint8_t idByte3 = bfc_uid & 0xFF;
  ucMACAddress[0] = 0x00;
  ucMACAddress[1] = 0x80;
  ucMACAddress[2] = 0xE1; // ST Micro MAC Prefix
  ucMACAddress[3] = idByte1;
  ucMACAddress[4] = idByte2;
  ucMACAddress[5] = idByte3;
  ucIPAddress[3] = idByte3; // Use last byte of ID for last byte of IP Address and hope for no conflicts
  snprintf(&bfc_name[strlen(bfc_name)], 7, "%.2X%.2X%.2X", idByte1, idByte2, idByte3);
  printf("BFC Name: %s\n", bfc_name);

  strcat(cmdTopic, bfc_name);
  strcat(cmdTopic, "/#");

  // Initialise the beamformer data structure
  int i, j;
  for (i=0;i<=7;i++) {
	  for (j=0;j<=15;j++) {
		  beamformer[i].lastXDelays[j] = 0;
		  beamformer[i].lastYDelays[j] = 0;
		  beamformer[i].nextXDelays[j] = 0;
		  beamformer[i].lastYDelays[j] = 0;
	  }
	  beamformer[i].lastTemp = -256.0;
	  beamformer[i].lastFlags = -1;
	  beamformer[i].lastPointTime = 0;
	  beamformer[i].nextPointTime = LONG_TIME_AWAY;
  }

  // Set unixTime from RTC
  RTC_DateTypeDef rtc_date;
  RTC_TimeTypeDef rtc_time;
  struct tm dateTime;
  HAL_RTC_GetTime(&hrtc, &rtc_time, RTC_FORMAT_BIN);
  HAL_RTC_GetDate(&hrtc, &rtc_date, RTC_FORMAT_BIN);
  printf("Startup Time: %04d-%02d-%02d - %02d:%02d:%02d\n", rtc_date.Year+2000, rtc_date.Month, rtc_date.Date, rtc_time.Hours, rtc_time.Minutes, rtc_time.Seconds);
  dateTime.tm_sec = rtc_time.Seconds;
  dateTime.tm_min = rtc_time.Minutes;
  dateTime.tm_hour = rtc_time.Hours;
  dateTime.tm_mday = rtc_date.Date;
  dateTime.tm_mon = rtc_date.Month -1;
  dateTime.tm_year = rtc_date.Year + 100;
  unixTime = mktime(&dateTime);
  printf("unixTime: %.lu\n", unixTime);

  FreeRTOS_IPInit( ucIPAddress, ucNetMask, ucGatewayAddress, ucDNSServerAddress, ucMACAddress );

  /* Infinite loop */
  for(;;)
  {
	  HAL_GPIO_TogglePin(LED1_GPIO_Port, LED1_Pin);
	  //printf("T: %.lu\n", unixTime);
	  if (unixTime > 10 && unixTime % 10 == 0) {
//		  RTC_DateTypeDef rtc_date;
//		  RTC_TimeTypeDef rtc_time;
//		  HAL_RTC_GetTime(&hrtc, &rtc_time, RTC_FORMAT_BIN);
//		  HAL_RTC_GetDate(&hrtc, &rtc_date, RTC_FORMAT_BIN);
//		  printf("Time: %.lu: %04d-%02d-%02d - %02d:%02d:%02d\n", unixTime, rtc_date.Year+2000, rtc_date.Month, rtc_date.Date, rtc_time.Hours, rtc_time.Minutes, rtc_time.Seconds);
	//	  doBFTest();
	  }
	  if (unixTime >= nextPointTime) {
		  //printf("%.lu: Time to send next pointing\n",unixTime);
		  sendBFPointing();
		  nextPointTime = LONG_TIME_AWAY;
		  for (int i=0; i<=7; i++) {
			  if (beamformer[i].nextPointTime < nextPointTime && beamformer[i].nextPointTime > unixTime + 1) nextPointTime = beamformer[i].nextPointTime;
		  }
		  if (nextPointTime <= unixTime) nextPointTime = LONG_TIME_AWAY;
	  }
	  if(xGlobalMqttAgentContext.mqttContext.connectStatus == MQTTConnected) {
		  if(taskMonitor == mask_TaskFlags) {
			  HAL_IWDG_Refresh(&hiwdg); // Pat the watchdog
			  taskMonitor = 0;
		  }
	  }
	  xReturn = xTaskNotifyWait( 0, 0xFFFFFFFF, NULL, pdMS_TO_TICKS(1000));
	  if (xReturn == pdTRUE) {
		  // We were flagged to do a BFTest
		  doBFTest();
	  }
  }
  /* USER CODE END StartDefaultTask */
}

void StartMQTTConn(void *argument)
{
  /* USER CODE BEGIN StartMQTTConn */
	ulGlobalEntryTimeMs = prvGetTimeMs();

	xNetworkContext.pParams = &xPlaintextTransportParams;

	/* Wait for Networking */
	if( FreeRTOS_IsNetworkUp() == pdFALSE )
	{
		LogInfo( ( "Waiting for the network link up event..." ) );

		while( FreeRTOS_IsNetworkUp() == pdFALSE )
		{
			vTaskDelay( pdMS_TO_TICKS( 1000U ) );
		}
	}

	/* Create the TCP connection to the broker, then the MQTT connection to the
	 * same. */
	BaseType_t xNetworkStatus = pdFAIL;
	MQTTStatus_t xMQTTStatus;
	MQTTContext_t * pMqttContext = &( xGlobalMqttAgentContext.mqttContext );

	/* Connect a TCP socket to the broker. */
	xNetworkStatus = prvSocketConnect( &xNetworkContext );
	configASSERT( xNetworkStatus == pdPASS );

	/* Initialize the MQTT context with the buffer and transport interface. */
	xMQTTStatus = prvMQTTInit();
	configASSERT( xMQTTStatus == MQTTSuccess );

	/* Form an MQTT connection without a persistent session. */
	xMQTTStatus = prvMQTTConnect( true );
	configASSERT( xMQTTStatus == MQTTSuccess );

  /* Infinite loop */
  do
  {
	/* MQTTAgent_CommandLoop() is effectively the agent implementation.  It
	* will manage the MQTT protocol until such time that an error occurs,
	* which could be a disconnect.  If an error occurs the MQTT context on
	* which the error happened is returned so there can be an attempt to
	* clean up and reconnect however the application writer prefers. */
	xMQTTStatus = MQTTAgent_CommandLoop( &xGlobalMqttAgentContext );

	/* Success is returned for disconnect or termination. The socket should
	* be disconnected. */
	if( ( xMQTTStatus == MQTTSuccess ) && ( xGlobalMqttAgentContext.mqttContext.connectStatus == MQTTNotConnected ) ) {
		/* MQTT Disconnect. Disconnect the socket. */
		xNetworkStatus = prvSocketDisconnect( &xNetworkContext );
		configASSERT( xNetworkStatus == pdPASS );
	} else if( xMQTTStatus == MQTTSuccess )	{
	  /* MQTTAgent_Terminate() was called, but MQTT was not disconnected. */
	  xMQTTStatus = MQTT_Disconnect( &( xGlobalMqttAgentContext.mqttContext ) );
	  configASSERT( xMQTTStatus == MQTTSuccess );
	  xNetworkStatus = prvSocketDisconnect( &xNetworkContext );
	  configASSERT( xNetworkStatus == pdPASS );
	} else {	/* Handle Error. */
	  /* Reconnect TCP. */
		xNetworkStatus = prvSocketDisconnect( &xNetworkContext );
		configASSERT( xNetworkStatus == pdPASS );
		xNetworkStatus = prvSocketConnect( &xNetworkContext );
		configASSERT( xNetworkStatus == pdPASS );
		pMqttContext->connectStatus = MQTTNotConnected;
		/* MQTT Connect with a persistent session. */
		xMQTTStatus = prvMQTTConnect( false );
		configASSERT( xMQTTStatus == MQTTSuccess );
		xMQTTStatus = 1; // Restart the command loop
	}
  } while (xMQTTStatus != MQTTSuccess);

  /* Should not get here.  Force an assert if the task exits from loop */
  configASSERT( 0 );

  /* USER CODE END StartMQTTConn */
}

void StartPingWD(void *argument) {
  /* USER CODE BEGIN StartPingWD */
	static SntpContext_t context;
	static uint8_t contextBuffer[ SNTP_BUFFER_SIZE ];
	static sntpNetworkContext_t udpContext;
	UdpTransportInterface_t udpTransportIntf;
	static SntpServerInfo_t pTimeServer;

    /* Set the UDP transport interface object. */
    udpTransportIntf.pUserContext = &udpContext;
    udpTransportIntf.sendTo = UdpTransport_Send;
    udpTransportIntf.recvFrom = UdpTransport_Recv;

    // Initialise time server
    pTimeServer.pServerName = SNTP_SERVER;
    pTimeServer.serverNameLen = strlen(SNTP_SERVER);
    pTimeServer.port = SNTP_DEFAULT_SERVER_PORT;

    /* Initialize context. */
	Sntp_Init( &context,
			   &pTimeServer,
			   1,
			   SNTP_RESPONSE_TIMEOUT_MS,
			   contextBuffer,
			   SNTP_BUFFER_SIZE,
			   resolveDns,
			   sntpClient_GetTime,
			   sntpClient_SetTime,
			   &udpTransportIntf,
			   NULL );

  /* Infinite loop */
  for(;;) {

	// Random time delay to avoid spamming the server on startup
	osDelay(100 + uxRand() % 1024);

    udpContext.socket = FreeRTOS_socket( FREERTOS_AF_INET, FREERTOS_SOCK_DGRAM, FREERTOS_IPPROTO_UDP );
    if (udpContext.socket != FREERTOS_INVALID_SOCKET) {
    	/* Use a random UDP port for SNTP communication with server */
    	struct freertos_sockaddr bindAddress;
		uint16_t randomPort = ( uxRand() % UINT16_MAX );
		bindAddress.sin_port = FreeRTOS_htons( randomPort );
		if( FreeRTOS_bind( udpContext.socket, &bindAddress, sizeof( bindAddress ) ) == 0 ) {
			SntpStatus_t status = Sntp_SendTimeRequest( &context, uxRand(), 60 );
			if (status == SntpSuccess) {
				do {
					status = Sntp_ReceiveTimeResponse( &context, 200 );
					osThreadYield();
				} while (status == SntpNoResponseReceived);
			}
			FreeRTOS_shutdown( udpContext.socket, FREERTOS_SHUT_RDWR );
			FreeRTOS_closesocket( udpContext.socket );
			if (status == SntpRejectedResponse) {
				osDelay(3000 + uxRand() % 2048);
			} else {
				osDelay(SNTP_POLL_INTERVAL + uxRand() % 4096);
			}
		}
    }
  }
  /* USER CODE END StartPingWD */
}

void StartTelemetry(void *argument) {
  /* USER CODE BEGIN StartTelemetry */
	BaseType_t xReturn;
	int i;
	osDelay(12000 + uxRand() % 2048); // short delay to let services connect

  /* Infinite loop */
  for(;;)
  {
	  for (i=0; i<=7; i++)
	  {
		  readI2Csensor(i, &beamformer[i].volts, &beamformer[i].amps, &beamformer[i].fault);
		  beamformer[i].last_read = unixTime;
	  }
	  bfController.temp = readTempSensor();
	  if(xGlobalMqttAgentContext.mqttContext.connectStatus == MQTTConnected) {
		  // Send new telemetry data - build JSON packet, publish to MQTT broker
		  cJSON *telemetryPacketJSON = cJSON_CreateObject();
		  cJSON_AddNumberToObject(telemetryPacketJSON, "time", unixTime);
		  char float_val[10];
		  snprintf(float_val, 9, "%.3f", bfController.temp);
		  cJSON_AddRawToObject(telemetryPacketJSON, "bfc_temp", float_val);
		  if (checkPowerAlarm()) {
			  cJSON_AddTrueToObject(telemetryPacketJSON, "pwr_gd");
		  } else {
			  cJSON_AddFalseToObject(telemetryPacketJSON, "pwr_gd");
		  }
		  cJSON *beamformerArrayJSON = cJSON_AddArrayToObject(telemetryPacketJSON, "bfs");
		  for (i=0; i<=7; i++) {
			  cJSON *bf_item = cJSON_CreateObject();
			  cJSON *doc_bool_item = NULL;
			  if (beamformer[i].doc_pwr) doc_bool_item = cJSON_CreateTrue();
			  else doc_bool_item = cJSON_CreateFalse();
			  cJSON_AddItemToObject(bf_item, "doc_pwr", doc_bool_item);
			  cJSON *bf_bool_item = NULL;
			  if (beamformer[i].bf_pwr) bf_bool_item = cJSON_CreateTrue();
			  else bf_bool_item = cJSON_CreateFalse();
			  cJSON_AddItemToObject(bf_item, "bf_pwr", bf_bool_item);
			  char float_val[10];
			  snprintf(float_val, 9, "%.2f", beamformer[i].volts);
			  cJSON *raw_item = cJSON_CreateRaw(float_val);
			  cJSON_AddItemToObject(bf_item, "bf_V", raw_item);
			  cJSON *int_item = cJSON_CreateNumber(beamformer[i].amps);
			  cJSON_AddItemToObject(bf_item, "bf_I", int_item);
			  cJSON *fault_bool_item = NULL;
			  if (beamformer[i].fault) fault_bool_item = cJSON_CreateTrue();
			  else fault_bool_item = cJSON_CreateFalse();
			  cJSON_AddItemToObject(bf_item, "bf_fault", fault_bool_item);

			  cJSON_AddNumberToObject(bf_item, "last_time", beamformer[i].lastPointTime);
			  snprintf(float_val, 9, "%.1f", beamformer[i].lastTemp);
			  cJSON_AddRawToObject(bf_item, "last_temp", float_val);
			  cJSON_AddNumberToObject(bf_item, "last_flags", beamformer[i].lastFlags);
			  cJSON_AddItemToArray(beamformerArrayJSON, bf_item);
		  }
		  char *payload = NULL;
		  payload = cJSON_PrintUnformatted(telemetryPacketJSON);
		  configASSERT(payload != NULL);

		  //printf("Telemetry payload: %s\n", payload);

		  MQTTPublishInfo_t xPublishInfo;
		  /* The context for the completion callback must stay in scope until
		   * the completion callback is invoked. In this case, using a stack variable
		   * is safe because the task waits for the callback to execute before continuing. */
		  MQTTAgentCommandContext_t xCommandContext;
		  MQTTAgentCommandInfo_t xCommandInformation;
		  char topic[25] = "telemetry/";
		  strcat(topic, bfc_name);

		  memset( (void *) &xPublishInfo, 0x00, sizeof( xPublishInfo ) );
		  xPublishInfo.qos = MQTTQoS0;
		  xPublishInfo.pTopicName = topic;
		  xPublishInfo.topicNameLength = (uint16_t) strlen(topic);
		  xPublishInfo.pPayload = payload;
		  xPublishInfo.payloadLength = strlen(payload);

		  memset( (void *) &xCommandContext, 0x00, sizeof( xCommandContext ) );
		  xCommandContext.xTaskToNotify = xTaskGetCurrentTaskHandle();
		  xCommandContext.ulCmdCounter = cmdCounter++;

		  xCommandInformation.cmdCompleteCallback = prvPublishCommandCallback;
		  xCommandInformation.pCmdCompleteCallbackContext = &xCommandContext;
		  xCommandInformation.blockTimeMs = MAX_COMMAND_SEND_BLOCK_TIME_MS;

		  MQTTStatus_t xCommandAdded = MQTTAgent_Publish(&xGlobalMqttAgentContext, &xPublishInfo, &xCommandInformation );

		  if( xCommandAdded == MQTTSuccess ) {
			  //printf("%s", "MQTT Publish command sent to agent thread successfully\n");
			  /* The command was successfully sent to the agent.  Note the data
			  pointed to by xPublishInfo.pTopicName and xPublishInfo.pPayload must
			  remain valid (not be lost from a stack frame or overwritten in a buffer)
			  until the PUBLISH is acknowledged. */
			  xReturn = xTaskNotifyWait( 0, 0, NULL, portMAX_DELAY ); /* Wait indefinitely. */

			  if( xReturn != pdFAIL )
			  {
				  /* The message was acknowledged and
				  xCommandContext.xReturnStatus holds the result of the operation. */
				  //printf("%s", "MQTT Publish command successfully acknowledged by broker\n");
			  }
		  }

		  cJSON_Delete(telemetryPacketJSON);
		  cJSON_free(payload);

	  }
	  // Wait until we're flagged to send telemetry again, or after the set period
	  // We need to wake up every 10s or so to set the task flag, so the watchdog gets pats
	  int msCounter = 0;
	  while (msCounter < TELEMETRY_PERIOD) {
		  if (msCounter + 10000 < TELEMETRY_PERIOD) {
			  taskMonitor |= taskflag_Telemetry; // Set the task flag to indicate task is still running
			  xTaskNotifyWait( 0, 0xFFFFFFFF, NULL, pdMS_TO_TICKS(10000));
		  } else {
			  taskMonitor |= taskflag_Telemetry; // Set the task flag to indicate task is still running
			  xTaskNotifyWait( 0, 0xFFFFFFFF, NULL, pdMS_TO_TICKS(TELEMETRY_PERIOD - msCounter));
		  }
		  msCounter += 10001;
	  }
  }
  /* USER CODE END StartTelemetry */
}

void StartLogging(void *argument) {

	for (;;) {
		while (logTail != logHead) { // There are log messages in the buffer to send
			// Publish a character string log message to log/bfc#
			if(xGlobalMqttAgentContext.mqttContext.connectStatus == MQTTConnected) {
				cJSON *logPacketJSON = cJSON_CreateObject();
				cJSON_AddNumberToObject(logPacketJSON, "time", unixTime);
				cJSON_AddStringToObject(logPacketJSON, logBuffer[logTail].logLevel, logBuffer[logTail].logMessage);
				char *payload = cJSON_PrintUnformatted(logPacketJSON);

				//printf("Payload: %s\n", payload);

				MQTTPublishInfo_t xPublishInfo;
				/* The context for the completion callback must stay in scope until
				* the completion callback is invoked. In this case, using a stack variable
				* is safe because the task waits for the callback to execute before continuing. */
				MQTTAgentCommandContext_t xCommandContext;
				MQTTAgentCommandInfo_t xCommandInformation;
				BaseType_t xReturn;
				char topic[20] = "log/";
				strcat(topic, bfc_name);

				memset( (void *) &xPublishInfo, 0x00, sizeof( xPublishInfo ) );
				xPublishInfo.qos = MQTTQoS0;
				xPublishInfo.pTopicName = topic;
				xPublishInfo.topicNameLength = (uint16_t) strlen(topic);
				xPublishInfo.pPayload = payload;
				xPublishInfo.payloadLength = strlen(payload);

				memset( (void *) &xCommandContext, 0x00, sizeof( xCommandContext ) );
				xCommandContext.xTaskToNotify = xTaskGetCurrentTaskHandle();
				xCommandContext.ulCmdCounter = cmdCounter++;

				xCommandInformation.cmdCompleteCallback = prvPublishCommandCallback;
				xCommandInformation.pCmdCompleteCallbackContext = &xCommandContext;
				xCommandInformation.blockTimeMs = MAX_COMMAND_SEND_BLOCK_TIME_MS;

				MQTTStatus_t xCommandAdded = MQTTAgent_Publish(&xGlobalMqttAgentContext, &xPublishInfo, &xCommandInformation );

				if( xCommandAdded == MQTTSuccess ) {
				  //printf("%s", "MQTT Publish command sent to agent thread successfully\n");
				  /* The command was successfully sent to the agent.  Note the data
				  pointed to by xPublishInfo.pTopicName and xPublishInfo.pPayload must
				  remain valid (not be lost from a stack frame or overwritten in a buffer)
				  until the PUBLISH is acknowledged. */
				  xReturn = xTaskNotifyWait( 0, 0, NULL, portMAX_DELAY ); /* Wait indefinitely. */

				  if( xReturn != pdFAIL )
				  {
					  /* The message was acknowledged and
					  xCommandContext.xReturnStatus holds the result of the operation. */
					  //printf("%s", "MQTT Publish command successfully acknowledged by broker\n");
					  if (++logTail > LOGBUFFSIZE) logTail = 0;
				  }
				} else {
					//printf("%s","Failed to enqueue message for MQTT Agent Publish - Log Message\n");
				}

				cJSON_Delete(logPacketJSON);
				cJSON_free(payload);
				osThreadYield();
			}
		}
		osDelay(107);
		taskMonitor |= taskflag_Logging; // Set the task flag to indicate task is still running
	}
}

/* USER CODE BEGIN Application */

void sendLog(const char *logLevel, const char *logMsg) {

	strncpy(logBuffer[logTail].logLevel, logLevel, 6);
	strncpy(logBuffer[logTail].logMessage, logMsg, 100);
	if (++logHead > LOGBUFFSIZE) logHead = 0;
	printf("%s: %s\n", logLevel, logMsg);
}

int checkPowerAlarm() {
	return HAL_GPIO_ReadPin(PRAlarm_GPIO_Port, PRAlarm_Pin);
}

void readI2Csensor(int sensorNum, float* bf_volts, int* bf_amps, int* bf_fault)
// Read the registers from one LTC4151 sensor and calculate the resulting values
{
	const uint16_t sensorAddr[8] = {BF1_SENSOR_ADDR, BF2_SENSOR_ADDR, BF3_SENSOR_ADDR, BF4_SENSOR_ADDR, BF5_SENSOR_ADDR, BF6_SENSOR_ADDR, BF7_SENSOR_ADDR, BF8_SENSOR_ADDR};
	uint8_t sData[8] = {0};
	uint32_t flag_ret;

	HAL_StatusTypeDef result = HAL_I2C_Master_Seq_Transmit_IT(&hi2c1, sensorAddr[sensorNum], (uint8_t*) sData, 1, I2C_FIRST_FRAME);
	if (result == HAL_OK) {
		// wait for transmission to finish, signalled by flag from callback function
		flag_ret = osEventFlagsWait(I2CSendCompleteHandle, EVENT_FLAG, osFlagsWaitAny, I2C_TIMEOUT);
		if (flag_ret != EVENT_FLAG) {
			// I2C error
			printf("I2C Timeout Error waiting for Addr Transmit: %d\n", (int)HAL_I2C_GetError(&hi2c1));
			I2C_Reset(&hi2c1);
		} else {
			result = HAL_I2C_Master_Seq_Receive_IT(&hi2c1, sensorAddr[sensorNum], (uint8_t*) sData, 6, I2C_LAST_FRAME);
			if (result == HAL_OK) {
				// wait for receive to finish, signalled by flag from callback function
				flag_ret = osEventFlagsWait(I2CReceiveCompleteHandle, EVENT_FLAG, osFlagsWaitAny, I2C_TIMEOUT);
				if (flag_ret != EVENT_FLAG) {
					// I2C error
					printf("I2C Timeout Error waiting for Data Receive: %d\n", (int)HAL_I2C_GetError(&hi2c1));
					I2C_Reset(&hi2c1);
				} else {
					// Successful read of 6 bytes of I2C sensor data - process into V & I
					uint16_t amps_int = ((uint16_t)sData[0] << 4) + ((sData[1] & 0xF0) >> 4);
					*bf_amps = (int) amps_int;
					uint16_t volts_int = ((uint16_t)sData[2] << 4) + ((sData[3] & 0xF0) >> 4);
					*bf_volts = (float) volts_int * 25e-3;
					uint16_t adc_int = (sData[4] << 4) + ((sData[5] & 0xF0) >> 4);
					if (volts_int > 1640 && adc_int > 810) *bf_fault = 0; else *bf_fault = 1;
				}
			} else {
				// Error on I2C receive
				printf("I2C HAL Error Receiving Data: %d\n", result);
				I2C_Reset(&hi2c1);
			}
		}
	} else {
		// Error on I2C transmit
		printf("I2C HAL Error Sending Register Addr: %d\n", result);
		I2C_Reset(&hi2c1);
	}

}

float readTempSensor() {
	uint32_t flag_ret;
	uint8_t sData[3] = {0};

	if (HAL_I2C_Master_Seq_Transmit_IT(&hi2c1, TEMP_SENSOR_ADDR, (uint8_t*) sData, 1, I2C_FIRST_FRAME) == HAL_OK) {
		// wait for transmission to finish, signalled by flag from callback function
		flag_ret = osEventFlagsWait(I2CSendCompleteHandle, EVENT_FLAG, osFlagsWaitAny, I2C_TIMEOUT);
		if (flag_ret != EVENT_FLAG) {
			// I2C error
			printf("%s", "readTempSensor: I2C Timeout Error waiting for Addr Transmit\n");
		}
		else {
			if (HAL_I2C_Master_Seq_Receive_IT(&hi2c1, TEMP_SENSOR_ADDR, (uint8_t*) sData, 2, I2C_LAST_FRAME) == HAL_OK) {
				// wait for receive to finish, signalled by flag from callback function
				flag_ret = osEventFlagsWait(I2CReceiveCompleteHandle, EVENT_FLAG, osFlagsWaitAny, I2C_TIMEOUT);
				if (flag_ret != EVENT_FLAG) {
					// I2C error
					printf("%s", "readTempSensor: I2C Timeout Error waiting for Data Receive\n");
				}
				else {
					// Successful read of 2 bytes of temp sensor data - process into float temp
					//printf("Read Temp Sensor, 0:%#.2x, 1:%#.2x\n",sData[0],sData[1]);
					int temp = sData[1] >> 5;
					temp += sData[0] << 3;
					return (float) temp * 0.125;
				}
			}
			else {
				// Error on I2C receive
				printf("%s", "readTempSensor: I2C HAL Error Receiving Data\n");
				I2C_Reset(&hi2c1);
			}
		}
	}
	else {
		// Error on I2C transmit
		printf("%s", "readTempSensor: I2C HAL Error Sending Register Addr\n");
		I2C_Reset(&hi2c1);
	}

	return -256.0;
}

void HAL_I2C_MasterTxCpltCallback (I2C_HandleTypeDef * hi2c) {
	uint32_t ret = osEventFlagsSet(I2CSendCompleteHandle, EVENT_FLAG);
	if (ret != EVENT_FLAG) {
		printf("%s", "HAL_I2C_MasterTxCpltCallback: Error setting flag\n");
	}
}

void HAL_I2C_MasterRxCpltCallback (I2C_HandleTypeDef * hi2c) {
	uint32_t ret = osEventFlagsSet(I2CReceiveCompleteHandle, EVENT_FLAG);
	if (ret != EVENT_FLAG) {
		printf("%s", "HAL_I2C_MasterRxCpltCallback: Error setting flag\n");
	}
}

void HAL_I2C_ErrorCallback(I2C_HandleTypeDef * hi2c) {
	printf("I2C Error, aborting...\n");
}

void I2C_Reset(I2C_HandleTypeDef *hi2c) {
	printf("I2C1 Reset\n");
	//HAL_I2C_DeInit(&hi2c);
	//osDelay(100);
	//HAL_I2C_Init(&hi2c);
	//osDelay(100);
}

void sendPointingResult() {
	if(xGlobalMqttAgentContext.mqttContext.connectStatus == MQTTConnected) {
		// Send result message - build JSON packet, publish to MQTT broker
		cJSON *resultPacketJSON = cJSON_CreateObject();
		cJSON_AddNumberToObject(resultPacketJSON, "time", bfController.lastPointTime);
		cJSON *bf_tempsJSON = cJSON_AddArrayToObject(resultPacketJSON, "bf_temps");
		int i;
		for (i=0; i<=7; i++) {
		  char float_val[10];
		  if (bfController.lastBFEnable & (0x01 << i)) snprintf(float_val, 9, "%.1f", bfController.lastBFTemps[i]);
		  else snprintf(float_val, 9, "%.1f", -256.0);
		  cJSON *raw_item = cJSON_CreateRaw(float_val);
		  cJSON_AddItemToArray(bf_tempsJSON, raw_item);
		}
		cJSON *bf_flagsJSON = cJSON_AddArrayToObject(resultPacketJSON, "bf_flags");
		for (i=0; i<=7; i++) {
			cJSON *int_item = NULL;
			if (bfController.lastBFEnable & (0x01 << i)) int_item = cJSON_CreateNumber(bfController.lastBFFlags[i]);
			else int_item = cJSON_CreateNumber(-1);
		  cJSON_AddItemToArray(bf_flagsJSON, int_item);
		}
		char *payload = NULL;
		payload = cJSON_PrintUnformatted(resultPacketJSON);

		//printf("Payload: %s\n", payload);

		MQTTPublishInfo_t xPublishInfo;
		/* The context for the completion callback must stay in scope until
		* the completion callback is invoked. In this case, using a stack variable
		* is safe because the task waits for the callback to execute before continuing. */
		MQTTAgentCommandContext_t xCommandContext;
		MQTTAgentCommandInfo_t xCommandInformation;
		BaseType_t xReturn;
		char topic[25] = "result/";
		strcat(topic, bfc_name);
		strcat(topic, "/point");

		memset( (void *) &xPublishInfo, 0x00, sizeof( xPublishInfo ) );
		xPublishInfo.qos = MQTTQoS0;
		xPublishInfo.pTopicName = topic;
		xPublishInfo.topicNameLength = (uint16_t) strlen(topic);
		xPublishInfo.pPayload = payload;
		xPublishInfo.payloadLength = strlen(payload);

		memset( (void *) &xCommandContext, 0x00, sizeof( xCommandContext ) );
		xCommandContext.xTaskToNotify = xTaskGetCurrentTaskHandle();
		xCommandContext.ulCmdCounter = cmdCounter++;

		xCommandInformation.cmdCompleteCallback = prvPublishCommandCallback;
		xCommandInformation.pCmdCompleteCallbackContext = &xCommandContext;
		xCommandInformation.blockTimeMs = MAX_COMMAND_SEND_BLOCK_TIME_MS;

		MQTTStatus_t xCommandAdded = MQTTAgent_Publish(&xGlobalMqttAgentContext, &xPublishInfo, &xCommandInformation );

		if( xCommandAdded == MQTTSuccess ) {
		  //printf("%s", "MQTT Publish command sent to agent thread successfully\n");
		  /* The command was successfully sent to the agent.  Note the data
		  pointed to by xPublishInfo.pTopicName and xPublishInfo.pPayload must
		  remain valid (not be lost from a stack frame or overwritten in a buffer)
		  until the PUBLISH is acknowledged. */
		  xReturn = xTaskNotifyWait( 0, 0, NULL, portMAX_DELAY ); /* Wait indefinitely. */

		  if( xReturn != pdFAIL )
		  {
			  /* The message was acknowledged and
			  xCommandContext.xReturnStatus holds the result of the operation. */
			  //printf("%s", "MQTT Publish command successfully acknowledged by broker\n");
		  }
		} else {
			//printf("%s","Failed to enqueue message for MQTT Agent Publish - Pointing Result\n");
		}

		cJSON_Delete(resultPacketJSON);
		cJSON_free(payload);
	}
}

/*-----------------------------------------------------------*/

static void prvPublishCommandCallback( MQTTAgentCommandContext_t * pxCommandContext,
                                       MQTTAgentReturnInfo_t * pxReturnInfo )
{
    /* Store the result in the application defined context so the task that
     * initiated the publish can check the operation's status. */
    pxCommandContext->xReturnStatus = pxReturnInfo->returnCode;

    if( pxCommandContext->xTaskToNotify != NULL )
    {
        /* Send the context's ulNotificationValue as the notification value so
         * the receiving task can check the value it set in the context matches
         * the value it receives in the notification. */
        xTaskNotify( pxCommandContext->xTaskToNotify,
                     pxCommandContext->ulCmdCounter,
                     eSetValueWithOverwrite );
    }
}

void vApplicationIPNetworkEventHook( eIPCallbackEvent_t eNetworkEvent ) {
static BaseType_t xTasksAlreadyCreated = pdFALSE;

    /* Both eNetworkUp and eNetworkDown events can be processed here. */
    if( eNetworkEvent == eNetworkUp ) {
        /* Create the tasks that use the TCP/IP stack if they have not already
        been created. */
        if( xTasksAlreadyCreated == pdFALSE )
        {
            /*
             * For convenience, tasks that use FreeRTOS-Plus-TCP can be created here
             * to ensure they are not created before the network is usable.
             */
        	/* creation of ManageMQTTConn */
        	ManageMQTTConnHandle = osThreadNew(StartMQTTConn, NULL, &ManageMQTTConn_attributes);

        	// Start logging thread
        	LoggingHandle = osThreadNew(StartLogging, NULL, &Logging_attributes);

        	/* creation of PingWatchdog */
        	PingWatchdogHandle = osThreadNew(StartPingWD, NULL, &PingWatchdog_attributes);

            xTasksAlreadyCreated = pdTRUE;
        }
    } else if (eNetworkEvent == eNetworkDown) {
    	vTaskDelete(ManageMQTTConnHandle);
    	vTaskDelete(LoggingHandle);
    	vTaskDelete(PingWatchdogHandle);
    	xTasksAlreadyCreated = pdFALSE;
    }
}

BaseType_t xApplicationGetRandomNumber( uint32_t * pulNumber ) {
	if (HAL_RNG_GenerateRandomNumber(&hrng, pulNumber) == HAL_OK) return pdTRUE; else return pdFALSE;
}

uint32_t ulApplicationGetNextSequenceNumber( uint32_t ulSourceAddress, uint16_t usSourcePort, uint32_t ulDestinationAddress, uint16_t usDestinationPort ) {
	uint32_t random = 0;
	if (HAL_RNG_GenerateRandomNumber(&hrng, &random) == HAL_OK) return random; else return 0U;
}

uint32_t uxRand() {
	uint32_t random = 0;
	if (HAL_RNG_GenerateRandomNumber(&hrng, &random) == HAL_OK) return random; else return 0U;
}

/*-----------------------------------------------------------*/

static void prvIncomingPublishCallback( MQTTAgentContext_t * pMqttAgentContext,
                                        uint16_t packetId,
                                        MQTTPublishInfo_t * pxPublishInfo ) {

	HAL_GPIO_TogglePin(LED3_GPIO_Port, LED3_Pin); //toggle pin when new message arrived
	printf("Incoming Publish: %.*s - %.*s\n",pxPublishInfo->topicNameLength, pxPublishInfo->pTopicName, pxPublishInfo->payloadLength, (char*)pxPublishInfo->pPayload);

	int incomingTopicID = CMD_TOPICERROR;
	const char* topic = pxPublishInfo->pTopicName;
	const char* substr = topic;
	// Decode topic string into an ID
	if (pxPublishInfo->topicNameLength > 6) {
		if(strncmp(topic, "command/", 8) == 0) {
			substr = topic + 8;
			if(strncmp(substr, bfc_name, strlen(bfc_name)) == 0) {
				substr += strlen(bfc_name) + 1;
				if(strncmp(substr, "bfs", 3) == 0) incomingTopicID = CMD_BFPWR;
				else if(strncmp(substr, "docs", 4) == 0) incomingTopicID = CMD_DOCPWR;
				else if(strncmp(substr, "time", 4) == 0) incomingTopicID = CMD_SETTIME;
				else if(strncmp(substr, "point", 5) == 0) incomingTopicID = CMD_POINT;
				else if(strncmp(substr, "bftest", 6) == 0) incomingTopicID = CMD_BFTEST;
				else if(strncmp(substr, "status", 6) == 0) incomingTopicID = CMD_STATUS;
				else incomingTopicID = CMD_TOPICERROR;
			} else incomingTopicID = CMD_TOPICERROR;
		} else incomingTopicID = CMD_TOPICERROR;
	}

	//printf("Command Decoded to: %d\n", incomingTopicID);

	uint8_t* data = (uint8_t*)pxPublishInfo->pPayload;
	int len = (int)pxPublishInfo->payloadLength;
	char errmsg[20];

	switch(incomingTopicID) {
		case CMD_POINT:
			parsePointing(data, len);
			break;
		case CMD_BFTEST:
			// bftest has no payload
			parseBFTest();
			break;
		case CMD_DOCPWR:
			parseDoCPower(data, len);
			vTaskDelay(200);
			xTaskNotify(TelemetryHandle, EVENT_FLAG, eSetValueWithOverwrite);
			break;
		case CMD_BFPWR:
			parseBFPower(data, len);
			vTaskDelay(200);
			xTaskNotify(TelemetryHandle, EVENT_FLAG, eSetValueWithOverwrite);
			break;
		case CMD_STATUS:
			// status has no payload
			xTaskNotify(TelemetryHandle, EVENT_FLAG, eSetValueWithOverwrite);
			break;
		case CMD_TOPICERROR:
			// Ignore the payload for invalid topics
			snprintf(errmsg, 20, "unknown command: %s", substr);
			sendLog("error",errmsg);
			break;
		case CMD_SETTIME:
			parseTime(data, len);
			break;
		}

}

/*-----------------------------------------------------------*/
void parseTime(const uint8_t *data, int len) {
	RTC_TimeTypeDef rtc_time;
	RTC_DateTypeDef rtc_date;
	struct tm dateTime;

	if (len > 0) {
		cJSON *command = cJSON_ParseWithLength((const char*) data, len);
		cJSON *time_data = cJSON_GetObjectItem(command, "time");
		if (time_data->valuedouble > 1677036957UL) {
			unixTime = time_data->valuedouble;
			uint32_t sec = unixTime;// + SNTP_UNIX_TIMESTAMP_DIFF;

			rtc_time.Hours = (sec/3600) % 24;
			rtc_time.Minutes = (sec/60) % 60;
			rtc_time.Seconds = sec % 60;
			rtc_time.SubSeconds = 107;
			rtc_time.DayLightSaving = RTC_DAYLIGHTSAVING_NONE;
			//rtc_time.StoreOperation = RTC_STOREOPERATION_RESET;

			localtime_r((time_t*) &sec, &dateTime);
			if (dateTime.tm_wday == 0) rtc_date.WeekDay = 7; else rtc_date.WeekDay = dateTime.tm_wday;
			rtc_date.Date = dateTime.tm_mday;
			rtc_date.Month = dateTime.tm_mon +1;
			rtc_date.Year = dateTime.tm_year % 100;

			HAL_RTC_SetTime(&hrtc, &rtc_time, RTC_FORMAT_BIN);
			HAL_RTC_SetDate(&hrtc, &rtc_date, RTC_FORMAT_BIN);
			char message[50];
			snprintf(message, 50, "Time set %.lu - %04d-%02d-%02d %02d:%02d:%02d", unixTime, rtc_date.Year+2000, rtc_date.Month, rtc_date.Date, rtc_time.Hours, rtc_time.Minutes, rtc_time.Seconds);
			//printf("%s\n", message);
			sendLog("info", message);
		} else {
			sendLog("error","error parsing time payload");
		}
	}
}

/*-----------------------------------------------------------*/
void parseBFTest() {
	if (nextPointTime - unixTime > 10) {
		xTaskNotify(defaultTaskHandle, EVENT_FLAG, eSetValueWithOverwrite);
	} else {
		//printf("Can't do BF Test, next pointing is too soon\n");
		sendLog("error", "Can't do BF Test, next pointing is too soon");
	}
}

/*-----------------------------------------------------------*/

static MQTTStatus_t prvMQTTInit( void )
{
    TransportInterface_t xTransport;
    MQTTStatus_t xReturn;
    MQTTFixedBuffer_t xFixedBuffer = { .pBuffer = xNetworkBuffer, .size = MQTT_AGENT_NETWORK_BUFFER_SIZE };
    //static uint8_t staticQueueStorageArea[ MQTT_AGENT_COMMAND_QUEUE_LENGTH * sizeof( MQTTAgentCommand_t * ) ];
    //static StaticQueue_t staticQueueStructure;
    MQTTAgentMessageInterface_t messageInterface =
    {
        .pMsgCtx        = NULL,
        .send           = Agent_MessageSend,
        .recv           = Agent_MessageReceive,
        .getCommand     = Agent_GetCommand,
        .releaseCommand = Agent_ReleaseCommand
    };

    LogDebug( ( "Creating command queue." ) );
    xCommandQueue.queue = xQueueCreate( MQTT_AGENT_COMMAND_QUEUE_LENGTH,
                                        sizeof( MQTTAgentCommand_t * ) );
    configASSERT( xCommandQueue.queue );
    messageInterface.pMsgCtx = &xCommandQueue;

    /* Initialize the task pool. */
    Agent_InitializePool();

    /* Fill in Transport Interface send and receive function pointers. */
    xTransport.pNetworkContext = &xNetworkContext;
	xTransport.send = Plaintext_FreeRTOS_send;
	xTransport.recv = Plaintext_FreeRTOS_recv;
	xTransport.writev = NULL;

    /* Initialize MQTT library. */
    xReturn = MQTTAgent_Init( &xGlobalMqttAgentContext,
                              &messageInterface,
                              &xFixedBuffer,
                              &xTransport,
                              prvGetTimeMs,
                              prvIncomingPublishCallback,
                              // Context to pass into the callback.
                              NULL );

    return xReturn;
}

/*-----------------------------------------------------------*/

static void prvMQTTClientSocketWakeupCallback( Socket_t pxSocket )
{
    MQTTAgentCommandInfo_t xCommandParams = { 0 };

    /* Just to avoid compiler warnings.  The socket is not used but the function
     * prototype cannot be changed because this is a callback function. */
    ( void ) pxSocket;

    /* A socket used by the MQTT task may need attention.  Send an event
     * to the MQTT task to make sure the task is not blocked on xCommandQueue. */
    if( ( uxQueueMessagesWaiting( xCommandQueue.queue ) == 0U ) && ( FreeRTOS_recvcount( pxSocket ) > 0 ) )
    {
        /* Don't block as this is called from the context of the IP task. */
        xCommandParams.blockTimeMs = 0U;
        MQTTAgent_ProcessLoop( &xGlobalMqttAgentContext, &xCommandParams );
    }
}

/*-----------------------------------------------------------*/

//static void prvSubscriptionCommandCallback( void * pxCommandContext,
//                                            MQTTAgentReturnInfo_t * pxReturnInfo )
//{
//    size_t lIndex = 0;
//    MQTTAgentSubscribeArgs_t * pxSubscribeArgs = ( MQTTAgentSubscribeArgs_t * ) pxCommandContext;
//
//    /* If the return code is success, no further action is required as all the topic filters
//     * are already part of the subscription list. */
//    if( pxReturnInfo->returnCode != MQTTSuccess )
//    {
//        /* Check through each of the suback codes and determine if there are any failures. */
//        for( lIndex = 0; lIndex < pxSubscribeArgs->numSubscriptions; lIndex++ )
//        {
//            /* This demo doesn't attempt to resubscribe in the event that a SUBACK failed. */
//            if( pxReturnInfo->pSubackCodes[ lIndex ] == MQTTSubAckFailure )
//            {
//                LogError( ( "Failed to resubscribe to topic %.*s.",
//                            pxSubscribeArgs->pSubscribeInfo[ lIndex ].topicFilterLength,
//                            pxSubscribeArgs->pSubscribeInfo[ lIndex ].pTopicFilter ) );
//            }
//        }
//
//        /* Hit an assert as some of the tasks won't be able to proceed correctly without
//         * the subscriptions. This logic will be updated with exponential backoff and retry.  */
//        configASSERT( pdTRUE );
//    }
//}

/*-----------------------------------------------------------*/

static MQTTStatus_t prvHandleResubscribe( void )
{
    MQTTStatus_t xResult = MQTTBadParameter;
    // Subscribe to Command topic
	MQTTSubscribeInfo_t xMQTTSubscription;
	uint16_t usSubscribePacketIdentifier = MQTT_GetPacketId( &(xGlobalMqttAgentContext.mqttContext) );

	( void ) memset( ( void * ) &xMQTTSubscription, 0x00, sizeof( xMQTTSubscription ) );
	xMQTTSubscription.qos = MQTTQoS0;
	xMQTTSubscription.pTopicFilter = cmdTopic;
	xMQTTSubscription.topicFilterLength = strlen( cmdTopic );

	xResult = MQTT_Subscribe( &(xGlobalMqttAgentContext.mqttContext), &xMQTTSubscription, 1, usSubscribePacketIdentifier );
	configASSERT(xResult == MQTTSuccess);

    return xResult;
}

/*-----------------------------------------------------------*/

static MQTTStatus_t prvMQTTConnect( bool xCleanSession )
{
    MQTTStatus_t xResult;
    MQTTConnectInfo_t xConnectInfo;
    bool xSessionPresent = false;
    MQTTPublishInfo_t willInfo = { 0 };

    memset( &xConnectInfo, 0x00, sizeof( xConnectInfo ) );
    xConnectInfo.cleanSession = xCleanSession;
    xConnectInfo.pClientIdentifier = bfc_name;
    xConnectInfo.clientIdentifierLength = ( uint16_t ) strlen( bfc_name );
    xConnectInfo.keepAliveSeconds = KEEP_ALIVE_INTERVAL_SECONDS;

    // The last will and testament is optional, it will be published by the broker
    // should this client disconnect without sending a DISCONNECT packet.
    char willTopic[20] = "status/";
    strcat(willTopic, bfc_name);
    willInfo.qos = MQTTQoS0;
    willInfo.pTopicName = willTopic;
    willInfo.topicNameLength = strlen( willInfo.pTopicName );
    willInfo.pPayload = "OFFLINE";
    willInfo.payloadLength = strlen("OFFLINE");
    willInfo.retain = true;

    // Send MQTT CONNECT packet to broker.
    xResult = MQTT_Connect( &( xGlobalMqttAgentContext.mqttContext ),
                            &xConnectInfo,
                            &willInfo,
                            CONNACK_RECV_TIMEOUT_MS,
                            &xSessionPresent );

    LogInfo( ( "Session present: %d\n", xSessionPresent ) );

    /* Resume a session if desired. */
    if( ( xResult == MQTTSuccess ) && ( xCleanSession == false ) )
    {
        xResult = MQTTAgent_ResumeSession( &xGlobalMqttAgentContext, xSessionPresent );

        /* Resubscribe to all the subscribed topics. */
        if( ( xResult == MQTTSuccess ) && ( xSessionPresent == false ) )
        {
            xResult = prvHandleResubscribe();
        }
    }

    // Publish Online Message
    char payload[30] = "Online ";
	RTC_DateTypeDef rtc_date;
	RTC_TimeTypeDef rtc_time;
	HAL_RTC_GetTime(&hrtc, &rtc_time, RTC_FORMAT_BIN);
	HAL_RTC_GetDate(&hrtc, &rtc_date, RTC_FORMAT_BIN);
	char date[20];
	char time[20];
	sprintf(date, "%04d-%02d-%02d - ", rtc_date.Year+2000, rtc_date.Month, rtc_date.Date);
	sprintf(time, "%02d:%02d:%02d", rtc_time.Hours, rtc_time.Minutes, rtc_time.Seconds);
	strcat(payload, date);
	strcat(payload, time);

	char topic[20] = "status/";
	strcat(topic, bfc_name);

	MQTTPublishInfo_t xPublishInfo;
	memset( (void *) &xPublishInfo, 0x00, sizeof( xPublishInfo ) );
	xPublishInfo.qos = MQTTQoS0;
	xPublishInfo.pTopicName = topic;
	xPublishInfo.topicNameLength = (uint16_t) strlen(topic);
	xPublishInfo.pPayload = payload;
	xPublishInfo.payloadLength = strlen(payload);
	xPublishInfo.retain = true;

	xResult = MQTT_Publish(&(xGlobalMqttAgentContext.mqttContext), &xPublishInfo, 0);

	// Subscribe to Command topic
	MQTTSubscribeInfo_t xMQTTSubscription;
	uint16_t usSubscribePacketIdentifier = MQTT_GetPacketId( &(xGlobalMqttAgentContext.mqttContext) );

	( void ) memset( ( void * ) &xMQTTSubscription, 0x00, sizeof( xMQTTSubscription ) );
	xMQTTSubscription.qos = MQTTQoS0;
	xMQTTSubscription.pTopicFilter = cmdTopic;
	xMQTTSubscription.topicFilterLength = strlen( cmdTopic );

	xResult = MQTT_Subscribe( &(xGlobalMqttAgentContext.mqttContext), &xMQTTSubscription, 1, usSubscribePacketIdentifier );
	configASSERT(xResult == MQTTSuccess);

    return xResult;
}

/*-----------------------------------------------------------*/

static BaseType_t prvSocketConnect( NetworkContext_t * pxNetworkContext )
{
    BaseType_t xConnected = pdPASS;
    BackoffAlgorithmStatus_t xBackoffAlgStatus = BackoffAlgorithmSuccess;
    BackoffAlgorithmContext_t xReconnectParams = { 0 };
    uint16_t usNextRetryBackOff = 0U;
    const TickType_t xTransportTimeout = 0UL;

    PlaintextTransportStatus_t xNetworkStatus = PLAINTEXT_TRANSPORT_CONNECT_FAILURE;

    /* We will use a retry mechanism with an exponential backoff mechanism and
     * jitter.  That is done to prevent a fleet of IoT devices all trying to
     * reconnect at exactly the same time should they become disconnected at
     * the same time. We initialize reconnect attempts and interval here. */
    BackoffAlgorithm_InitializeParams( &xReconnectParams,
                                       RETRY_BACKOFF_BASE_MS,
                                       RETRY_MAX_BACKOFF_DELAY_MS,
                                       RETRY_MAX_ATTEMPTS );

    if( xConnected == pdPASS )
    {
        /* Attempt to connect to MQTT broker. If connection fails, retry after a
         * timeout. Timeout value will exponentially increase until the maximum
         * number of attempts are reached.
         */
        do
        {
			LogInfo( ( "Creating a TCP connection to %s:%d.",
					   MQTT_BROKER_ENDPOINT,
					   MQTT_BROKER_PORT ) );
			xNetworkStatus = Plaintext_FreeRTOS_Connect( pxNetworkContext,
														 MQTT_BROKER_ENDPOINT,
														 MQTT_BROKER_PORT,
														 TRANSPORT_SEND_RECV_TIMEOUT_MS,
														 TRANSPORT_SEND_RECV_TIMEOUT_MS );
			xConnected = ( xNetworkStatus == PLAINTEXT_TRANSPORT_SUCCESS ) ? pdPASS : pdFAIL;

            if( !xConnected )
            {
                /* Get back-off value (in milliseconds) for the next connection retry. */
                xBackoffAlgStatus = BackoffAlgorithm_GetNextBackoff( &xReconnectParams, uxRand(), &usNextRetryBackOff );

                if( xBackoffAlgStatus == BackoffAlgorithmSuccess )
                {
                    LogWarn( ( "Connection to the broker failed. "
                               "Retrying connection in %hu ms.",
                               usNextRetryBackOff ) );
                    vTaskDelay( pdMS_TO_TICKS( usNextRetryBackOff ) );
                }
            }

            if( xBackoffAlgStatus == BackoffAlgorithmRetriesExhausted )
            {
                LogError( ( "Connection to the broker failed, all attempts exhausted." ) );
            }
        } while( ( xConnected != pdPASS ) && ( xBackoffAlgStatus == BackoffAlgorithmSuccess ) );
    }

    /* Set the socket wakeup callback and ensure the read block time. */
    if( xConnected )
    {
        ( void ) FreeRTOS_setsockopt( pxNetworkContext->pParams->tcpSocket,
                                      0, /* Level - Unused. */
                                      FREERTOS_SO_WAKEUP_CALLBACK,
                                      ( void * ) prvMQTTClientSocketWakeupCallback,
                                      sizeof( &( prvMQTTClientSocketWakeupCallback ) ) );

        ( void ) FreeRTOS_setsockopt( pxNetworkContext->pParams->tcpSocket,
                                      0,
                                      FREERTOS_SO_RCVTIMEO,
                                      &xTransportTimeout,
                                      sizeof( TickType_t ) );
    }

    return xConnected;
}

/*-----------------------------------------------------------*/

static BaseType_t prvSocketDisconnect( NetworkContext_t * pxNetworkContext )
{
    BaseType_t xDisconnected = pdFAIL;

    /* Set the wakeup callback to NULL since the socket will disconnect. */
    ( void ) FreeRTOS_setsockopt( pxNetworkContext->pParams->tcpSocket,
                                  0, /* Level - Unused. */
                                  FREERTOS_SO_WAKEUP_CALLBACK,
                                  ( void * ) NULL,
                                  sizeof( void * ) );

        LogInfo( ( "Disconnecting TCP connection.\n" ) );
        PlaintextTransportStatus_t xNetworkStatus = PLAINTEXT_TRANSPORT_CONNECT_FAILURE;
        xNetworkStatus = Plaintext_FreeRTOS_Disconnect( pxNetworkContext );
        xDisconnected = ( xNetworkStatus == PLAINTEXT_TRANSPORT_SUCCESS ) ? pdPASS : pdFAIL;

    return xDisconnected;
}

/*-----------------------------------------------------------*/

static uint32_t prvGetTimeMs( void )
{
    TickType_t xTickCount = 0;
    uint32_t ulTimeMs = 0UL;

    /* Get the current tick count. */
    xTickCount = xTaskGetTickCount();

    /* Convert the ticks to milliseconds. */
    ulTimeMs = ( uint32_t ) xTickCount * MILLISECONDS_PER_TICK;

    /* Reduce ulGlobalEntryTimeMs from obtained time so as to always return the
     * elapsed time in the application. */
    ulTimeMs = ( uint32_t ) ( ulTimeMs - ulGlobalEntryTimeMs );

    return ulTimeMs;
}

/*-----------------------------------------------------------*/

/********************** DNS Resolution Interface *******************************/
static BaseType_t resolveDns( const SntpServerInfo_t * pServerAddr,
                        uint32_t * pIpV4Addr )
{
    uint32_t resolvedAddr = 0;
    BaseType_t status = 0;

    resolvedAddr = FreeRTOS_gethostbyname( pServerAddr->pServerName );

    /* Set the output parameter if DNS look up succeeded. */
    if( resolvedAddr != 0 )
    {
        /* DNS Look up succeeded. */
        status = 1;

        *pIpV4Addr = FreeRTOS_ntohl( resolvedAddr );

        #if defined( LIBRARY_LOG_LEVEL ) && ( LIBRARY_LOG_LEVEL != LOG_NONE )
            uint8_t stringAddr[ 16 ];
            FreeRTOS_inet_ntoa( resolvedAddr, stringAddr );
            LogInfo( ( "Resolved time server as %s", stringAddr ) );
        #endif
    }

    return status;
}

/**************************** Time Interfaces ************************************************/
static void sntpClient_GetTime( SntpTimestamp_t * pCurrentTime ) {
    pCurrentTime->seconds = unixTime + SNTP_TIME_AT_UNIX_EPOCH_SECS;
    pCurrentTime->fractions = 0;
}

static void sntpClient_SetTime( const SntpServerInfo_t * pTimeServer,
                                const SntpTimestamp_t * pServerTime,
                                int64_t clockOffsetMs,
                                SntpLeapSecondInfo_t leapSecondInfo ) {

    //printf("Received time from time server: %s\n", pTimeServer->pServerName);

    SntpStatus_t status;
    uint32_t unixSecs;
    uint32_t unixMicroSecs;

    /* Convert server time from NTP timestamp to UNIX format. */
    status = Sntp_ConvertToUnixTime( pServerTime,
                                     &unixSecs,
                                     &unixMicroSecs );
    if ( status == SntpSuccess ) {
    	unixTime = unixSecs;
    	uint32_t tim2Counter = 84000000 - (unixMicroSecs * 84);
    	htim2.Instance->CNT = tim2Counter;
		//printf("SNTP: Time set to %.lu s, TIM2: %.lu\n", unixTime, tim2Counter);

    	RTC_TimeTypeDef rtc_time;
		RTC_DateTypeDef rtc_date;
		struct tm dateTime;

		rtc_time.Hours = (unixSecs/3600) % 24;
		rtc_time.Minutes = (unixSecs/60) % 60;
		rtc_time.Seconds = unixSecs % 60;
		rtc_time.SubSeconds = 107;
		rtc_time.DayLightSaving = RTC_DAYLIGHTSAVING_NONE;
		//rtc_time.StoreOperation = RTC_STOREOPERATION_RESET;

		localtime_r((time_t*) &unixSecs, &dateTime);
		if (dateTime.tm_wday == 0) rtc_date.WeekDay = 7; else rtc_date.WeekDay = dateTime.tm_wday;
		rtc_date.Date = dateTime.tm_mday;
		rtc_date.Month = dateTime.tm_mon +1;
		rtc_date.Year = dateTime.tm_year % 100;

		HAL_RTC_SetTime(&hrtc, &rtc_time, RTC_FORMAT_BIN);
		HAL_RTC_SetDate(&hrtc, &rtc_date, RTC_FORMAT_BIN);

    }

}

/********************** UDP Interface definition *******************************/
int32_t UdpTransport_Send( sntpNetworkContext_t * pNetworkContext,
                           uint32_t serverAddr,
                           uint16_t serverPort,
                           const void * pBuffer,
                           uint16_t bytesToSend )
{
    struct freertos_sockaddr destinationAddress;
    int32_t bytesSent;

    destinationAddress.sin_addr = FreeRTOS_htonl( serverAddr );
    destinationAddress.sin_port = FreeRTOS_htons( serverPort );

    /* Send the buffer with ulFlags set to 0, so the FREERTOS_ZERO_COPY bit
     * is clear. */
    bytesSent = FreeRTOS_sendto(
        pNetworkContext->socket, /* The socket being send to. */
        pBuffer, /* The data being sent. */
        bytesToSend, /* The length of the data being sent. */
        0, /* ulFlags with the FREERTOS_ZERO_COPY bit clear. */
        &destinationAddress, /* Where the data is being sent. */
        sizeof( destinationAddress ) /* Not used but should be set as shown. */
        );

    return bytesSent;
}

static int32_t UdpTransport_Recv( sntpNetworkContext_t * pNetworkContext,
                                  uint32_t serverAddr,
                                  uint16_t serverPort,
                                  void * pBuffer,
                                  uint16_t bytesToRecv )
{
    struct freertos_sockaddr sourceAddress;
    int32_t bytesReceived;
    socklen_t addressLength = sizeof( struct freertos_sockaddr );

    /* Receive into the buffer with ulFlags set to 0, so the FREERTOS_ZERO_COPY bit
     * is clear. */
    bytesReceived = FreeRTOS_recvfrom(
        pNetworkContext->socket, /* The socket data is being received on. */
        pBuffer, /* The buffer into which received data will be copied. */
        bytesToRecv, /* The length of the buffer into which data will be copied. */
        0, /* ulFlags with the FREERTOS_ZERO_COPY bit clear. */
        &sourceAddress, /* Will get set to the source of the received data. */
        &addressLength /* Not used but should be set as shown. */
        );

    /* If data is received from the network, discard the data if  received from a different source than
     * the server. */
    if( ( bytesReceived > 0 ) && ( ( FreeRTOS_ntohl( sourceAddress.sin_addr ) != serverAddr ) ||
                                   ( FreeRTOS_ntohs( sourceAddress.sin_port ) != serverPort ) ) )
    {
        bytesReceived = 0;

        #if defined( LIBRARY_LOG_LEVEL ) && ( LIBRARY_LOG_LEVEL != LOG_NONE )
            /* Convert the IP address of the sender's address to string for logging. */
            char stringAddr[ 16 ];
            FreeRTOS_inet_ntoa( sourceAddress.sin_addr, stringAddr );

            /* Log about reception of packet from unexpected sender. */
            LogWarn( ( "Received UDP packet from unexpected source: Addr=%s Port=%u",
                       stringAddr, FreeRTOS_ntohs( sourceAddress.sin_port ) ) );
        #endif
    }

    /* Translate the return code of timeout to the UDP transport interface expected
     * code to indicate read retry. */
    else if( bytesReceived == -pdFREERTOS_ERRNO_EWOULDBLOCK )
    {
        bytesReceived = 0;
    }

    return bytesReceived;
}

/* USER CODE END Application */
